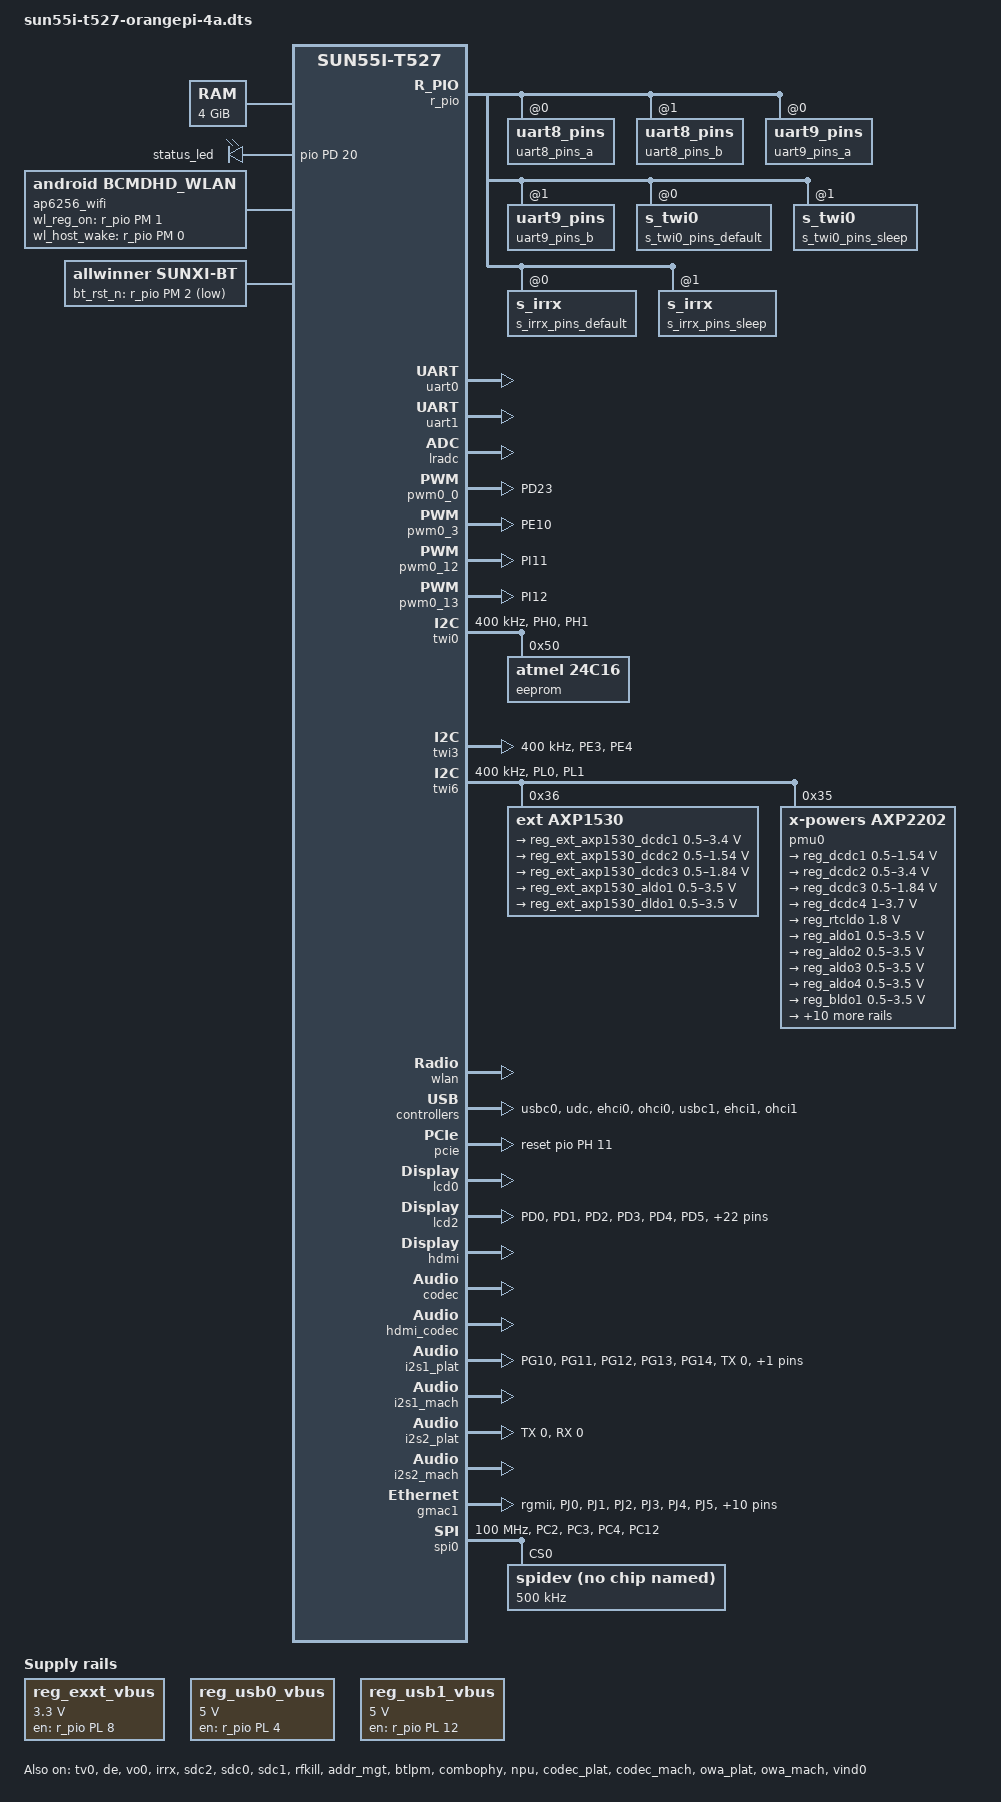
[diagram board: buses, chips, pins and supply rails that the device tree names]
/*
 * Allwinner Technology CO., Ltd.
 */

/dts-v1/;

#include "sun55iw3p1.dtsi"

/{
	board = "A527", "A527-PRO2-AXP717C";
	compatible = "allwinner,a523", "arm,sun55iw3p1";

	chosen {
		stdout-path = "serial0:115200n8";
	};

	memory {
		reg = <0x00 0x40000000 0x01 0x00>;
		device_type = "memory";
	};

	aliases {
		pmu0 = &pmu0;
		axp1530 = &axp1530;
		serial0 = &uart0;
		lcd0 = &lcd0;
		hdmi = &hdmi;
		//reg-tcs0 = &reg_tcs0;
		//reg-sy0 = &reg_sy0;
		reg-axp1530 = &reg_ext_axp1530_dcdc1;
		//tcs0 = &tcs0;
		//sy0 = &sy0;
		cpu-ext = &cpu4;
		standby-param = &standby_param;
		arisc-config = &arisc_config;
	};

        leds: gpio-leds {
		compatible = "gpio-leds";
		pinctrl-names = "default";
		status = "okay";

		status_led@0 {
			gpios = <&pio PD 20 GPIO_ACTIVE_HIGH>;
			label = "status_led";
			linux,default-trigger = "heartbeat";
			linux,default-trigger-delay-ms = <0>;
		};
	};

	ap6256_wifi: ap6256_wifi {
		compatible = "android,bcmdhd_wlan";
		gpio_wl_reg_on = <&r_pio PM 1 GPIO_ACTIVE_HIGH>;
		gpio_wl_host_wake = <&r_pio PM 0 GPIO_ACTIVE_HIGH>;
	};

        //unisoc_uwe_bsp: uwe-bsp {
        //        compatible = "unisoc,uwe_bsp";
        //        wl-reg-on = <&r_pio PM 1 GPIO_ACTIVE_HIGH>;
        //        bt-reg-on = <&r_pio PM 2 GPIO_ACTIVE_LOW>;
        //        wl-wake-host-gpio = <&r_pio PM 0 GPIO_ACTIVE_HIGH>;
        //        bt-wake-host-gpio = <&r_pio PM 5 GPIO_ACTIVE_HIGH>;
        //        //sdio-ext-int-gpio = <&gpio2 RK_PC1 GPIO_ACTIVE_HIGH>;
        //        unisoc,btwf-file-name = "/vendor/etc/firmware/wcnmodem.bin";
        //        //adma-tx;
        //        //adma-rx;
        //        data-irq;
        //        blksz-512;
        //        keep-power-on;
        //        status = "okay";
        //};

        //sprd-mtty {
        //        compatible = "sprd,mtty";
        //        sprd,name = "ttyBT";
        //        status = "okay";
        //};

	reg_exxt_vbus: exxt-vbus {
		compatible = "regulator-fixed";
		regulator-name = "exxxxt-vbus";
		regulator-min-microvolt = <3300000>;
		regulator-max-microvolt = <3300000>;
		regulator-enable-ramp-delay = <1000>;
		gpio = <&r_pio PL 8 GPIO_ACTIVE_HIGH>;
		regulator-always-on;
		regulator-boot-on;
		enable-active-high;
	};

	reg_usb0_vbus: usb0-vbus {
		compatible = "regulator-fixed";
		regulator-name = "usb0-vbus";
		regulator-min-microvolt = <5000000>;
		regulator-max-microvolt = <5000000>;
		regulator-enable-ramp-delay = <1000>;
		gpio = <&r_pio PL 4 GPIO_ACTIVE_HIGH>;
		regulator-always-on;
		regulator-boot-on;
		enable-active-high;
	};

	reg_usb1_vbus: usb1-vbus {
		compatible = "regulator-fixed";
		regulator-name = "usb1-vbus";
		regulator-min-microvolt = <5000000>;
		regulator-max-microvolt = <5000000>;
		regulator-enable-ramp-delay = <1000>;
		gpio = <&r_pio PL 12 GPIO_ACTIVE_HIGH>;
		enable-active-high;
	};

	standby_param: standby_param {
		vdd-cpu = <0x00000001>;
		vdd-cpub = <0x00000001>;
		vdd-ndr = <0x00000004>;
		vdd-sys = <0x00000002>;
		vcc-pll = <0x00000080>;
		vcc-io  = <0x00004000>;

		osc24m-on = <0x0>;
	};

	arisc_config: arisc_config {
		s_uart_config{
			pins = "PL2", "PL3";
			function = <2>, <2>;
			status = "disabled";
		};
	};

	edp_panel: edp_panel {
		compatible = "edp-general-panel";
		status = "disabled";
		power0-supply = <&reg_dcdc4>;
		enable0-gpios = <&pio PD 21 GPIO_ACTIVE_HIGH>;

		backlight = <&edp_panel_backlight>;

		panel-timing {
			clock-frequency = <125000000>; /* pixel clock */
			hactive = <1920>;
			hback-porch = <180>;
			hfront-porch = <120>;
			hsync-len = <32>;
			vactive = <1080>;
			vback-porch = <10>;
			vfront-porch = <10>;
			vsync-len = <20>;
			/* hor_sync_polarity */
			hsync-active = <0>;
			/* ver_sync_polarity */
			vsync-active = <0>;

			// unused now
			/*
			de-active = <1>;
			pixelclk-active = <1>;
			syncclk-active = <0>;
			interlaced;
			doublescan;
			doubleclk;
			*/
		};
		ports {
			#address-cells = <1>;
			#size-cells = <0>;
			panel_edp_in: port@0 {
				#address-cells = <1>;
				#size-cells = <0>;
				reg = <0>;
				edp_panel_in: endpoint@0 {
					reg = <0>;
					remote-endpoint = <&edp_panel_out>;
				};
			};
		};
	};

	edp_panel_backlight: edp-panel-backlight {
		compatible = "pwm-backlight";
		status = "disabled";
		brightness-levels = <
			  0   1   2   3   4   5   6   7
			  8   9  10  11  12  13  14  15
			 16  17  18  19  20  21  22  23
			 24  25  26  27  28  29  30  31
			 32  33  34  35  36  37  38  39
			 40  41  42  43  44  45  46  47
			 48  49  50  51  52  53  54  55
			 56  57  58  59  60  61  62  63
			 64  65  66  67  68  69  70  71
			 72  73  74  75  76  77  78  79
			 80  81  82  83  84  85  86  87
			 88  89  90  91  92  93  94  95
			 96  97  98  99 100 101 102 103
			104 105 106 107 108 109 110 111
			112 113 114 115 116 117 118 119
			120 121 122 123 124 125 126 127
			128 129 130 131 132 133 134 135
			136 137 138 139 140 141 142 143
			144 145 146 147 148 149 150 151
			152 153 154 155 156 157 158 159
			160 161 162 163 164 165 166 167
			168 169 170 171 172 173 174 175
			176 177 178 179 180 181 182 183
			184 185 186 187 188 189 190 191
			192 193 194 195 196 197 198 199
			200 201 202 203 204 205 206 207
			208 209 210 211 212 213 214 215
			216 217 218 219 220 221 222 223
			224 225 226 227 228 229 230 231
			232 233 234 235 236 237 238 239
			240 241 242 243 244 245 246 247
			248 249 250 251 252 253 254 255>;
		default-brightness-level = <200>;
		pwms = <&pwm0 0 50000 0>;
	};

	backlight0: backlight0 {
		compatible = "pwm-backlight";
		status = "disabled";
		brightness-levels = <
			  0   1   2   3   4   5   6   7
			  8   9  10  11  12  13  14  15
			 16  17  18  19  20  21  22  23
			 24  25  26  27  28  29  30  31
			 32  33  34  35  36  37  38  39
			 40  41  42  43  44  45  46  47
			 48  49  50  51  52  53  54  55
			 56  57  58  59  60  61  62  63
			 64  65  66  67  68  69  70  71
			 72  73  74  75  76  77  78  79
			 80  81  82  83  84  85  86  87
			 88  89  90  91  92  93  94  95
			 96  97  98  99 100 101 102 103
			104 105 106 107 108 109 110 111
			112 113 114 115 116 117 118 119
			120 121 122 123 124 125 126 127
			128 129 130 131 132 133 134 135
			136 137 138 139 140 141 142 143
			144 145 146 147 148 149 150 151
			152 153 154 155 156 157 158 159
			160 161 162 163 164 165 166 167
			168 169 170 171 172 173 174 175
			176 177 178 179 180 181 182 183
			184 185 186 187 188 189 190 191
			192 193 194 195 196 197 198 199
			200 201 202 203 204 205 206 207
			208 209 210 211 212 213 214 215
			216 217 218 219 220 221 222 223
			224 225 226 227 228 229 230 231
			232 233 234 235 236 237 238 239
			240 241 242 243 244 245 246 247
			248 249 250 251 252 253 254 255>;
		default-brightness-level = <200>;
		pwms = <&pwm0 3 50000 0>;
	};

	panel_0: panel_0@0 {
		compatible = "allwinner,panel-dsi";
		status = "disabled";
		reg = <0>;
		power0-supply = <&reg_cldo4>;
		power1-supply = <&reg_cldo1>;

		enable0-gpios = <&pio PE 13 GPIO_ACTIVE_HIGH>;
		reset-gpios = <&pio PE 14 GPIO_ACTIVE_HIGH>;
		reset-num = <1>;
		backlight = <&backlight0>;
		dsi,flags = <MIPI_DSI_MODE_VIDEO>;
		dsi,lanes = <4>;
		dsi,format = <0>;
		enable-delay-ms = <500>;
		reset-delay-ms = <500>;
		panel-init-sequence = [
				39 10 04 FF 98 81 03

				39 10 02 01 00
				39 10 02 02 00
				39 10 02 03 53
				39 10 02 04 D3
				39 10 02 05 00
				39 10 02 06 0D
				39 10 02 07 08
				39 10 02 08 00
				39 10 02 09 00
				39 10 02 0a 00
				39 10 02 0b 00
				39 10 02 0c 00
				39 10 02 0d 00
				39 10 02 0e 00
				39 10 02 0f 28
				39 10 02 10 28
				39 10 02 11 00
				39 10 02 12 00
				39 10 02 13 00
				39 10 02 14 00
				39 10 02 15 00
				39 10 02 16 00
				39 10 02 17 00
				39 10 02 18 00
				39 10 02 19 00
				39 10 02 1a 00
				39 10 02 1b 00
				39 10 02 1c 00
				39 10 02 1d 00
				39 10 02 1e 40
				39 10 02 1f 80
				39 10 02 20 06
				39 10 02 21 01
				39 10 02 22 00
				39 10 02 23 00
				39 10 02 24 00
				39 10 02 25 00
				39 10 02 26 00
				39 10 02 27 00
				39 10 02 28 33
				39 10 02 29 33
				39 10 02 2a 00
				39 10 02 2b 00
				39 10 02 2c 00
				39 10 02 2d 00
				39 10 02 2e 00
				39 10 02 2f 00
				39 10 02 30 00
				39 10 02 31 00
				39 10 02 32 00
				39 10 02 33 00
				39 10 02 34 03
				39 10 02 35 00
				39 10 02 36 00
				39 10 02 37 00
				39 10 02 38 96
				39 10 02 39 00
				39 10 02 3a 00 
				39 10 02 3b 00
				39 10 02 3c 00
				39 10 02 3d 00
				39 10 02 3e 00
				39 10 02 3f 00
				39 10 02 40 00
				39 10 02 41 00
				39 10 02 42 00
				39 10 02 43 00  
				39 10 02 44 00

				39 10 02 50 00
				39 10 02 51 23
				39 10 02 52 45
				39 10 02 53 67
				39 10 02 54 89
				39 10 02 55 AB
				39 10 02 56 01
				39 10 02 57 23
				39 10 02 58 45
				39 10 02 59 67
				39 10 02 5a 89
				39 10 02 5b AB
				39 10 02 5c CD
				39 10 02 5d EF

				39 10 02 5e 00
				39 10 02 5f 08
				39 10 02 60 08
				39 10 02 61 06
				39 10 02 62 06
				39 10 02 63 01
				39 10 02 64 01
				39 10 02 65 00
				39 10 02 66 00
				39 10 02 67 02
				39 10 02 68 15
				39 10 02 69 15
				39 10 02 6a 14
				39 10 02 6b 14
				39 10 02 6c 0D
				39 10 02 6d 0D
				39 10 02 6e 0C
				39 10 02 6f 0C
				39 10 02 70 0F
				39 10 02 71 0F
				39 10 02 72 0E
				39 10 02 73 0E
				39 10 02 74 02

				39 10 02 75 08
				39 10 02 76 08
				39 10 02 77 06
				39 10 02 78 06
				39 10 02 79 01
				39 10 02 7a 01
				39 10 02 7b 00
				39 10 02 7c 00
				39 10 02 7d 02
				39 10 02 7e 15
				39 10 02 7f 15
				39 10 02 80 14
				39 10 02 81 14
				39 10 02 82 0D
				39 10 02 83 0D
				39 10 02 84 0C
				39 10 02 85 0C
				39 10 02 86 0F
				39 10 02 87 0F
				39 10 02 88 0E
				39 10 02 89 0E
				39 10 02 8A 02

				39 10 04 FF 98 81 04

				39 10 02 6E 2B
				39 10 02 6F 37
				39 10 02 3A A4
				39 10 02 8D 1A
				39 10 02 87 BA
				39 10 02 B2 D1
				39 10 02 88 0B
				39 10 02 38 01
				39 10 02 39 00
				39 10 02 B5 07
				39 10 02 31 75
				39 10 02 3B 98

				39 10 04 FF 98 81 01
				39 10 02 43 33
				39 10 02 22 0A
				39 10 02 31 00
				39 10 02 53 48
				39 10 02 55 48
				39 10 02 50 99
				39 10 02 51 94
				39 10 02 60 10
				39 10 02 62 20

				39 10 02 A0 00
				39 10 02 A1 00
				39 10 02 A2 15
				39 10 02 A3 14
				39 10 02 A4 1B
				39 10 02 A5 2F
				39 10 02 A6 25
				39 10 02 A7 24
				39 10 02 A8 80
				39 10 02 A9 1F
				39 10 02 AA 2C
				39 10 02 AB 6C
				39 10 02 AC 16
				39 10 02 AD 14
				39 10 02 AE 4D
				39 10 02 AF 20
				39 10 02 B0 29
				39 10 02 B1 4F
				39 10 02 B2 5F
				39 10 02 B3 23

				39 10 02 C0 00
				39 10 02 C1 2E
				39 10 02 C2 3B
				39 10 02 C3 15
				39 10 02 C4 16
				39 10 02 C5 28
				39 10 02 C6 1A
				39 10 02 C7 1C
				39 10 02 C8 A7
				39 10 02 C9 1B
				39 10 02 CA 28
				39 10 02 CB 92
				39 10 02 CC 1F
				39 10 02 CD 1C
				39 10 02 CE 4B
				39 10 02 CF 1F
				39 10 02 D0 28
				39 10 02 D1 4E
				39 10 02 D2 5C
				39 10 02 D3 23

				39 10 04 FF 98 81 00
				39 10 02 11 00
				39 78 02 29 00
				39 10 02 35 00
		];

		panel-exit-sequence = [
			05 14 01 28
			05 50 01 10
		];

		display-timings {
			native-mode = <&dsi1_timing0>;

			dsi1_timing0: timing0 {
				clock-frequency = <68215200>;
				hback-porch = <20>;
				hactive = <800>;
				hfront-porch = <20>;
				hsync-len = <20>;
				vback-porch = <8>;
				vactive = <1280>;
				vfront-porch = <30>;
				vsync-len = <4>;
			};
		};
		port {
			panel0_in: endpoint@0 {
				reg = <0>;
				remote-endpoint = <&panel_output_0>;
			};
		};
	};
};

/* HDMI DRM */
&tv0 {
        status = "okay";
};

&tv1 {
        status = "disabled";
};

&de {
	chn_cfg_mode = <3>;
	status = "okay";
};

&vo0 {
	status = "okay";
};

//&vo1 {
//	status = "disabled";
//};

&dlcd1 {
	status = "disabled";
};

&dsi1combophy {
	status = "disabled";
};

&dsi1 {
	status = "disabled";
	pinctrl-0 = <&dsi1_4lane_pins_a>;
	pinctrl-1 = <&dsi1_4lane_pins_b>;
	pinctrl-names = "active","sleep";

	ports {
		dsi1_out: port@1{
			dsi1_out_panel: endpoint {
				remote-endpoint = <&panel_input>;
			};
		};
	};
	panel: panel@0 {
		compatible = "allwinner,virtual-panel";
		status = "disabled";
		reg = <0>;
		ports {
			panel_in: port@0 {
				reg = <0>;
				panel_input: endpoint@0 {
					reg = <0>;
					remote-endpoint = <&dsi1_out_panel>;
				};
			};
			panel_out: port@1 {
				reg = <1>;
				panel_output_0: endpoint@0 {
					reg = <0>;
					remote-endpoint = <&panel0_in>;
				};
			};
		};
	};
};

&drm_edp {
	status = "disabled";

	//edp_ssc_en = <0>;
	//edp_ssc_mode = <0>;
	//edp_psr_support = <0>;
	edp_colordepth = <8>; /* 6/8/10/12/16 */
	edp_color_fmt = <0>; /* 0:RGB  1: YUV444  2: YUV422 */

	//lane1_sw = <0>;
	//lane1_pre = <0>;
	//lane2_sw = <0>;
	//lane2_pre = <0>;
	//lane3_sw = <0>;
	//lane3_pre = <0>;
	//efficient_training = <0>;

	//sink_capacity_prefer = <1>;
	//edid_timings_prefer = <1>;
	//timings_fixed = <1>;

	vcc-edp-supply = <&reg_bldo3>;
	vdd-edp-supply = <&reg_dcdc2>;
	panel = <&edp_panel>;

	ports {
		edp_out: port@1 {
			edp_panel_out: endpoint@0 {
				reg = <0>;
				remote-endpoint = <&edp_panel_in>;
			};
		};
	};
};

&r_pio {
	uart8_pins_a: uart8_pins@0 {
		pins = "PL2", "PL3";
		function = "s_uart0";
	};

	uart8_pins_b: uart8_pins@1 {
		pins = "PL2", "PL3";
		function = "gpio_in";
	};

	uart9_pins_a: uart9_pins@0 {
		pins = "PM0", "PM1";
		function = "s_uart1";
	};

	uart9_pins_b: uart9_pins@1 {
		pins = "PM0", "PM1";
		function = "gpio_in";
	};

	s_twi0_pins_default: s_twi0@0 {
		pins = "PL0", "PL1";
		function = "s_twi0";
		drive-strength = <10>;
		bias-pull-up;
	};

	s_twi0_pins_sleep: s_twi0@1 {
		pins = "PL0", "PL1";
		function = "gpio_in";
	};

	s_irrx_pins_default: s_irrx@0 {
		pins = "PL11";
		function = "s_cir";
	};

	s_irrx_pins_sleep: s_irrx@1 {
	        pins = "PL11";
		function = "gpio_in";
	};
};

&pio {
	vcc-pg-supply = <&reg_pio1_8>;
	vcc-pc-supply = <&reg_pio1_8>;
	vcc-pf-supply = <&reg_pio1_8>;
	vcc-pfo-supply = <&reg_pio3_3>;

	uart0_pins_a: uart0_pins@0 {
		pins = "", "";
		function = "uart0";
	};

	uart0_pins_b: uart0_pins@1 {
		pins = "", "";
		function = "gpio_in";
	};

	uart2_pins_a: uart2_pins@0 {
		pins = "PB0", "PB1";
		function = "uart2";
	};

	uart2_pins_b: uart2_pins@1 {
		pins = "PB0", "PB1";
		function = "gpio_in";
	};

	uart3_pins_a: uart3_pins@0 {
		pins = "PI11", "PI12";
		function = "uart3";
	};

	uart3_pins_b: uart3_pins@1 {
		pins = "PI11", "PI12";
		function = "gpio_in";
	};

	uart4_pins_a: uart4_pins@0 {
		pins = "PI0", "PI1";
		function = "uart4";
	};

	uart4_pins_b: uart4_pins@1 {
		pins = "PI0", "PI1";
		function = "gpio_in";
	};

	uart5_pins_a: uart5_pins@0 {
		pins = "PI2", "PI3";
		function = "uart5";
	};

	uart5_pins_b: uart5_pins@1 {
		pins = "PI2", "PI3";
		function = "gpio_in";
	};

	uart6_pins_a: uart6_pins@0 {
		pins = "PI6", "PI7";
		function = "uart6";
	};

	uart6_pins_b: uart6_pins@1 {
		pins = "PI6", "PI7";
		function = "gpio_in";
	};

	uart7_pins_a: uart7_pins@0 {
		pins = "PB13", "PB14";
		function = "uart7";
	};

	uart7_pins_b: uart7_pins@1 {
		pins = "PB13", "PB14";
		function = "gpio_in";
	};

	pwm0_0_pin_active: pwm0_0@0 {
		pins = "PD23";
		function = "pwm0_0";
		drive-strength = <10>;
	};
	
	pwm0_0_pin_sleep: pwm0_0@1 {
		pins = "PD23";
		function = "gpio_in";
	};
	
	pwm0_1_pin_active: pwm0_1@0 {
		pins = "PI0";
		function = "pwm0_1";
		drive-strength = <10>;
	};
	
	pwm0_1_pin_sleep: pwm0_1@1 {
		pins = "PI0";
		function = "gpio_in";
	};
	
	pwm0_2_pin_active: pwm0_2@0 {
		pins = "PB11";
		function = "pwm0_2";
		drive-strength = <10>;
	};
	
	pwm0_2_pin_sleep: pwm0_2@1 {
		pins = "PB11";
		function = "gpio_in";
	};
	
	pwm0_3_pin_active: pwm0_3@0 {
		pins = "PE10";
		function = "pwm0_3";
		drive-strength = <10>;
	};
	
	pwm0_3_pin_sleep: pwm0_3@1 {
		pins = "PE10";
		function = "gpio_in";
	};
	
	pwm0_4_pin_active: pwm0_4@0 {
		pins = "PB13";
		function = "pwm0_4";
		drive-strength = <10>;
	};
	
	pwm0_4_pin_sleep: pwm0_4@1 {
		pins = "PB13";
		function = "gpio_in";
	};
	
	pwm0_5_pin_active: pwm0_5@0 {
		pins = "PB14";
		function = "pwm0_5";
		drive-strength = <10>;
	};
	
	pwm0_5_pin_sleep: pwm0_5@1 {
		pins = "PB14";
		function = "gpio_in";
	};
	
	pwm0_6_pin_active: pwm0_6@0 {
		pins = "PB0";
		function = "pwm0_6";
		drive-strength = <10>;
	};
	
	pwm0_6_pin_sleep: pwm0_6@1 {
		pins = "PB0";
		function = "gpio_in";
	};
	
	pwm0_7_pin_active: pwm0_7@0 {
		pins = "PB1";
		function = "pwm0_7";
		drive-strength = <10>;
	};
	
	pwm0_7_pin_sleep: pwm0_7@1 {
		pins = "PB1";
		function = "gpio_in";
	};

	pwm0_8_pin_active: pwm0_8@0 {
		pins = "PB4";
		function = "pwm0_8";
		drive-strength = <10>;
	};

	pwm0_8_pin_sleep: pwm0_8@1 {
		pins = "PB4";
		function = "gpio_in";
	};

	pwm0_9_pin_active: pwm0_9@0 {
		pins = "PB5";
		function = "pwm0_9";
		drive-strength = <10>;
	};
	
	pwm0_9_pin_sleep: pwm0_9@1 {
		pins = "PB5";
		function = "gpio_in";
	};
	
	pwm0_10_pin_active: pwm0_10@0 {
		pins = "PB6";
		function = "pwm0_10";
		drive-strength = <10>;
	};
	
	pwm0_10_pin_sleep: pwm0_10@1 {
		pins = "PB6";
		function = "gpio_in";
	};
	
	pwm0_11_pin_active: pwm0_11@0 {
		pins = "PB7";
		function = "pwm0_11";
		drive-strength = <10>;
	};
	
	pwm0_11_pin_sleep: pwm0_11@1 {
		pins = "PB7";
		function = "gpio_in";
	};

	pwm0_12_pin_active: pwm0_12@0 {
		pins = "PI11";
		function = "pwm0_12";
		drive-strength = <10>;
	};

	pwm0_12_pin_sleep: pwm0_12@1 {
		pins = "PI11";
		function = "gpio_in";
	};

	pwm0_13_pin_active: pwm0_13@0 {
		pins = "PI12";
		function = "pwm0_13";
		drive-strength = <10>;
	};

	pwm0_13_pin_sleep: pwm0_13@1 {
		pins = "PI12";
		function = "gpio_in";
	};

	pwm0_14_pin_active: pwm0_14@0 {
		pins = "PI13";
		function = "pwm0_14";
		drive-strength = <10>;
	};
	
	pwm0_14_pin_sleep: pwm0_14@1 {
		pins = "PI13";
		function = "gpio_in";
	};
	
	pwm0_15_pin_active: pwm0_15@0 {
		pins = "PI14";
		function = "pwm0_15";
		drive-strength = <10>;
	};
	
	pwm0_15_pin_sleep: pwm0_15@1 {
		pins = "PI14";
		function = "gpio_in";
	};

	ledc_pins_a: ledc@0 {
		pins = "PE5";
		function = "ledc";
		drive-strength = <10>;
	};

	ledc_pins_b: ledc@1 {
		pins = "PE5";
		function = "gpio_in";
	};

	irrx_pins_default: irrx@0 {
		pins = "PH19";
		function = "cir";
	};

	irrx_pins_sleep: irrx@1 {
	        pins = "PH19";
	        function = "gpio_in";
	};

	irtx_pins_default: irtx@0 {
		pins = "PH18";
		function = "cir";
	};

	irtx_pins_sleep: irtx@1 {
		pins = "PH18";
		function = "gpio_in";
	};

	twi0_pins_default: twi0@0 {
		pins = "PH0", "PH1";
		function = "twi0";
		drive-strength = <40>;
		bias-pull-up;
	};

	twi0_pins_sleep: twi0@1 {
		pins = "PH0", "PH1";
		function = "gpio_in";
	};

	twi1_pins_default: twi1@0 {
		pins = "PB4", "PB5";
		function = "twi1";
		drive-strength = <10>;
		bias-pull-up;
	};

	twi1_pins_sleep: twi1@1 {
		pins = "PB4", "PB5";
		function = "gpio_in";
	};

	twi3_pins_default: twi3@0 {
		pins = "PE3", "PE4";
		function = "twi3";
		drive-strength = <40>;
		bias-pull-up;
	};

	twi3_pins_sleep: twi3@1 {
		pins = "PE3", "PE4";
		function = "twi3";
		drive-strength = <40>;
		bias-pull-up;
	};

	twi4_pins_default: twi4@0 {
		pins = "PI0", "PI1";
		function = "twi4";
		drive-strength = <20>;
		bias-pull-up;
	};

	twi4_pins_sleep: twi4@1 {
		pins = "PI0", "PI1";
		function = "gpio_in";
	};

	twi5_pins_default: twi5@0 {
		pins = "PI8", "PI9";
		function = "twi5";
		drive-strength = <10>;
		bias-pull-up;
	};

	twi5_pins_sleep: twi5@1 {
		pins = "PI8", "PI9";
		function = "gpio_in";
	};

	rgb24_pins_a: rgb24@0 {
		pins = "PD0", "PD1", "PD2", "PD3", "PD4", "PD5", "PD6", "PD7", "PD8", "PD9", \
			"PD10", "PD11", "PD12", "PD13", "PD14", "PD15", "PD16", "PD17", "PD18", "PD19", \
			"PD20", "PD21", "PD22","PD23","PD24","PD25","PD26","PD27";
		      function = "dpss";
		      drive-strength = <30>;
	      };
	rgb24_pins_b: rgb24@1 {
		pins = "PD0", "PD1", "PD2", "PD3", "PD4", "PD5", "PD6", "PD7", "PD8", "PD9", \
			"PD10", "PD11", "PD12", "PD13", "PD14", "PD15", "PD16", "PD17", "PD18", "PD19", \
			"PD20", "PD21", "PD22", "PD23","PD24","PD25","PD26","PD27";
		      function = "gpio_in";
	      };
	lvds0_pins_a: lvds0@0 {
		pins = "PD0", "PD1", "PD2", "PD3", "PD4", "PD5", "PD6", "PD7", "PD8", "PD9";
		      function = "lvds";
		      drive-strength = <30>;
	      };
	lvds0_pins_b: lvds0@1 {
		      pins = "PD0", "PD1", "PD2", "PD3", "PD4", "PD5", "PD6", "PD7", "PD8", "PD9";
		      function = "gpio_in";
	      };

	csi_mclk3_pins_a: csi_mclk3@0 {
		pins = "PE10";
		function = "mipi3";
		drive-strength = <20>;
	};

	csi_mclk3_pins_b: csi_mclk3@1 {
		pins = "PE10";
		function = "gpio_in";
	};

	ncsi_pins_a: ncsi@0 {
		pins = "PK12", "PK14", "PK15",
		"PK16", "PK17", "PK18", "PK19",
		"PK20", "PK21", "PK22", "PK23",
		"PE6", "PE7", "PE8", "PE9",
		"PE10", "PE11", "PE12", "PE15";
		function = "ncsi";
		drive-strength = <20>;
	};

	ncsi_pins_b: ncsi@1 {
		pins = "PK12", "PK14", "PK15",
		"PK16", "PK17", "PK18", "PK19",
		"PK20", "PK21", "PK22", "PK23",
		"PE6", "PE7", "PE8", "PE9",
		"PE10", "PE11", "PE12", "PE15";
		function = "gpio_in";
	};

	i2s1_pins_a: i2s1@0 {
		pins = "PG10", "PG11", "PG12";
		function = "i2s1";
		drive-strength = <20>;
		bias-disable;
	};

	i2s1_pins_b: i2s1@1 {
		pins = "PG10", "PG11", "PG12", "PG13", "PG14";
		function = "io_disabled";
		drive-strength = <20>;
		bias-disable;
	};

	i2s1_pins_c: i2s1@2 {
		pins = "PG13";
		function = "i2s1_dout";
		drive-strength = <20>;
		bias-disable;
	};

	i2s1_pins_d: i2s1@3 {
		pins = "PG14";
		function = "i2s1_din";
		drive-strength = <20>;
		bias-disable;
	};

	owa_pins_a: owa@0 {
		pins = "PH7";
		function = "owa";
		drive-strength = <20>;
		bias-disable;
	};

	owa_pins_b: owa@1 {
		pins = "PH7";
		function = "io_disabled";
		drive-strength = <20>;
		bias-disable;
	};

	nand0_pins_default: nand0@0 {
		pins = "PC0", "PC1", "PC2", "PC5",
			 "PC8", "PC9", "PC10", "PC11",
			 "PC12", "PC13", "PC14", "PC15",
			 "PC16";
		function = "nand0";
		drive-strength = <30>;
	};

	nand0_pins_rb: nand0@1 {
		pins = "PC4", "PC6", "PC3", "PC7";
		function = "nand0";
		drive-strength = <30>;
		bias-pull-up;   /* only RB&CE should be pulled up */
	};

	nand0_pins_sleep: nand0@2 {
		pins = "PC0", "PC1", "PC2", "PC3",
			 "PC4", "PC5", "PC6", "PC7",
			 "PC8", "PC9", "PC10", "PC11",
			 "PC12", "PC13", "PC14", "PC15",
			 "PC16";
		function = "io_disabled";
		drive-strength = <10>;
	};

	i2s0_pins_a: i2s0@0 {
		pins = "PB4", "PB5", "PB6";
		function = "i2s0";
		drive-strength = <20>;
		bias-disable;
	};

	i2s0_pins_b: i2s0@1 {
		pins = "PB4", "PB5", "PB6", "PB7", "PB8";
		function = "io_disabled";
		drive-strength = <20>;
		bias-disable;
	};

	i2s0_pins_c: i2s0@2 {
		pins = "PB7";
		function = "i2s0_dout";
		drive-strength = <20>;
		bias-disable;
	};

	i2s0_pins_d: i2s0@3 {
		pins = "PB8";
		function = "i2s0_din";
		drive-strength = <20>;
		bias-disable;
	};

	gmac1_pins_default: gmac1@0 {
		pins = "PJ0", "PJ1", "PJ2", "PJ3",
			"PJ4", "PJ5", "PJ6", "PJ7",
			"PJ8", "PJ9", "PJ10", "PJ11",
			"PJ12","PJ13", "PJ14", "PJ15";
		drive-strength = <40>;
		function = "gmac1";
		bias-pull-up;
	};

	gmac1_pins_sleep: gmac1@1 {
		pins = "PJ0", "PJ1", "PJ2", "PJ3",
			"PJ4", "PJ5", "PJ6", "PJ7",
			"PJ8", "PJ9", "PJ10", "PJ11",
			"PJ12","PJ13", "PJ14", "PJ15";
		function = "gpio_in";
	};

	spi0_pin_default: spi0_pin_default{
		pins = "PC2","PC3","PC4","PC12";
		function = "spi0";
	};

	spi0_pin_sleep: spi0_pin_sleep{
		pins = "PC2","PC3","PC4","PC12";
		function = "gpio_in";
	};

	spi1_pin_default: spi1_pin_default{
		pins = "PI2","PI3","PI4","PI5";
		function = "spi1";
	};

	spi1_pin_sleep: spi1_pin_sleep{
		pins = "PI2","PI3","PI4","PI5";
		function = "gpio_in";
	};

	spi2_pin_default: spi2_pin_default{
		pins = "PB0","PB1","PB2","PB3";
		function = "spi2";
	};

	spi2_pin_sleep: spi2_pin_sleep{
		pins = "PB0","PB1","PB2","PB3";
		function = "gpio_in";
	};
};

&soc {
	auto_print@54321 {
		reg = <0x0 0x54321 0x0 0x0>;
		device_type = "auto_print";
		status = "okay";
	};

	hall_para {
		hall_name = "MH248";
		status = "okay";
		hall_int_port = <&r_pio PL 9 GPIO_ACTIVE_LOW>;
	};

};

&uart0 {
	pinctrl-names = "default", "sleep";
	pinctrl-0 = <&uart0_pins_a>;
	pinctrl-1 = <&uart0_pins_b>;
	uart-supply = <&reg_cldo3>;
	status = "okay";
};

&uart1 {
	status = "okay";
};

&uart2 {
	pinctrl-names = "default", "sleep";
	pinctrl-0 = <&uart2_pins_a>;
	pinctrl-1 = <&uart2_pins_b>;
	status = "disabled";
};

&uart3 {
	pinctrl-names = "default", "sleep";
	pinctrl-0 = <&uart3_pins_a>;
	pinctrl-1 = <&uart3_pins_b>;
	status = "disabled";
};

&uart4 {
	pinctrl-names = "default", "sleep";
	pinctrl-0 = <&uart4_pins_a>;
	pinctrl-1 = <&uart4_pins_b>;
	status = "disabled";
};

&uart5 {
	pinctrl-names = "default", "sleep";
	pinctrl-0 = <&uart5_pins_a>;
	pinctrl-1 = <&uart5_pins_b>;
	status = "disabled";
};

&uart6 {
	pinctrl-names = "default", "sleep";
	pinctrl-0 = <&uart6_pins_a>;
	pinctrl-1 = <&uart6_pins_b>;
	status = "disabled";
};

&uart7 {
	pinctrl-names = "default", "sleep";
	pinctrl-0 = <&uart7_pins_a>;
	pinctrl-1 = <&uart7_pins_b>;
	status = "disabled";
};

&uart8 {
	pinctrl-names = "default", "sleep";
	pinctrl-0 = <&uart8_pins_a>;
	pinctrl-1 = <&uart8_pins_b>;
	status = "disabled";
};

&uart9 {
	pinctrl-names = "default", "sleep";
	pinctrl-0 = <&uart9_pins_a>;
	pinctrl-1 = <&uart9_pins_b>;
	status = "disabled";
};

&lradc {
	key_cnt = <2>;
	key0 = <646 115>;
	key1 = <900 114>;
	key_debounce;
	debounce_value = <150>;
	status = "okay";
};

&gpadc0 {
	channel_num = <2>;
	channel_select = <3>;
	channel_data_select = <3>;
	channel_compare_select = <3>;
	channel_cld_select = <3>;
	channel_chd_select = <3>;
	channel0_compare_lowdata = <1700000>;
	channel0_compare_higdata = <1200000>;
	channel1_compare_lowdata = <460000>;
	channel1_compare_higdata = <1200000>;
	status = "disabled";
};

&gpadc1 {
	channel_num = <2>;
	channel_select = <3>;
	channel_data_select = <3>;
	channel_compare_select = <3>;
	channel_cld_select = <3>;
	channel_chd_select = <3>;
	channel0_compare_lowdata = <1700000>;
	channel0_compare_higdata = <1200000>;
	channel1_compare_lowdata = <460000>;
	channel1_compare_higdata = <1200000>;
	status = "disabled";
};

&pwm0_0 {
	pinctrl-names = "active", "sleep";
	pinctrl-0 = <&pwm0_0_pin_active>;
	pinctrl-1 = <&pwm0_0_pin_sleep>;
	status = "okay";
};

&pwm0_1 {
	pinctrl-names = "active", "sleep";
	pinctrl-0 = <&pwm0_1_pin_active>;
	pinctrl-1 = <&pwm0_1_pin_sleep>;
	status = "disabled";
};

&pwm0_2 {
	pinctrl-names = "active", "sleep";
	pinctrl-0 = <&pwm0_2_pin_active>;
	pinctrl-1 = <&pwm0_2_pin_sleep>;
	status = "disabled";
};

&pwm0_3 {
	pinctrl-names = "active", "sleep";
	pinctrl-0 = <&pwm0_3_pin_active>;
	pinctrl-1 = <&pwm0_3_pin_sleep>;
	status = "okay";
};

&pwm0_4 {
	pinctrl-names = "active", "sleep";
	pinctrl-0 = <&pwm0_4_pin_active>;
	pinctrl-1 = <&pwm0_4_pin_sleep>;
	status = "disabled";
};

&pwm0_5 {
	pinctrl-names = "active", "sleep";
	pinctrl-0 = <&pwm0_5_pin_active>;
	pinctrl-1 = <&pwm0_5_pin_sleep>;
	status = "disabled";
};

&pwm0_6 {
	pinctrl-names = "active", "sleep";
	pinctrl-0 = <&pwm0_6_pin_active>;
	pinctrl-1 = <&pwm0_6_pin_sleep>;
	status = "disabled";
};

&pwm0_7 {
	pinctrl-names = "active", "sleep";
	pinctrl-0 = <&pwm0_7_pin_active>;
	pinctrl-1 = <&pwm0_7_pin_sleep>;
	status = "disabled";
};

&pwm0_8 {
	pinctrl-names = "active", "sleep";
	pinctrl-0 = <&pwm0_8_pin_active>;
	pinctrl-1 = <&pwm0_8_pin_sleep>;
	status = "disabled";
};

&pwm0_9 {
	pinctrl-names = "active", "sleep";
	pinctrl-0 = <&pwm0_9_pin_active>;
	pinctrl-1 = <&pwm0_9_pin_sleep>;
	status = "disabled";
};

&pwm0_10 {
	pinctrl-names = "active", "sleep";
	pinctrl-0 = <&pwm0_10_pin_active>;
	pinctrl-1 = <&pwm0_10_pin_sleep>;
	status = "disabled";
};

&pwm0_11 {
	pinctrl-names = "active", "sleep";
	pinctrl-0 = <&pwm0_11_pin_active>;
	pinctrl-1 = <&pwm0_11_pin_sleep>;
	status = "disabled";
};

&pwm0_12 {
	pinctrl-names = "active", "sleep";
	pinctrl-0 = <&pwm0_12_pin_active>;
	pinctrl-1 = <&pwm0_12_pin_sleep>;
	status = "okay";
};

&pwm0_13 {
	pinctrl-names = "active", "sleep";
	pinctrl-0 = <&pwm0_13_pin_active>;
	pinctrl-1 = <&pwm0_13_pin_sleep>;
	status = "okay";
};

&pwm0_14 {
	pinctrl-names = "active", "sleep";
	pinctrl-0 = <&pwm0_14_pin_active>;
	pinctrl-1 = <&pwm0_14_pin_sleep>;
	status = "disabled";
};

&pwm0_15 {
	pinctrl-names = "active", "sleep";
	pinctrl-0 = <&pwm0_15_pin_active>;
	pinctrl-1 = <&pwm0_15_pin_sleep>;
	status = "disabled";
};

&ledc  {
	pinctrl-names = "default", "sleep";
	pinctrl-0 = <&ledc_pins_a>;
	pinctrl-1 = <&ledc_pins_b>;
	led_count = <34>;
	output_mode = "GRB";
	reset_ns = <84>;
	t1h_ns = <800>;
	t1l_ns = <320>;
	t0h_ns = <300>;
	t0l_ns = <800>;
	wait_time0_ns = <84>;
	wait_time1_ns = <84>;
	wait_data_time_ns = <600000>;
	status = "disabled";
};

&irrx {
	pinctrl-names = "default", "sleep";
	pinctrl-0 = <&irrx_pins_default>;
	pinctrl-1 = <&irrx_pins_sleep>;
	status = "okay";
};

&s_irrx {
	pinctrl-names = "default", "sleep";
	pinctrl-0 = <&s_irrx_pins_default>;
	pinctrl-1 = <&s_irrx_pins_sleep>;
	status = "disabled";
};

&irtx {
	pinctrl-names = "default", "sleep";
	pinctrl-0 = <&irtx_pins_default>;
	pinctrl-1 = <&irtx_pins_sleep>;
	status = "disabled";
};

&twi0 {
	clock-frequency = <400000>;
	pinctrl-0 = <&twi0_pins_default>;
	pinctrl-1 = <&twi0_pins_sleep>;
	pinctrl-names = "default", "sleep";
	/* For stability and backwards compatibility, we recommend setting ‘twi_drv_used’ to 1 */
	twi_drv_used = <1>;
	status = "okay";

	eeprom@50 {
		compatible = "atmel,24c16";
		reg = <0x50>;
		status = "okay";
	};
	pcie_usb_phy@74 {
		compatible = "combphy,phy74";
		reg = <0x74>;
		status = "disabled";
	};
	pcie_usb_phy@75 {
		compatible = "combphy,phy75";
		reg = <0x75>;
		status = "disabled";
	};

	//ctp: ctp@0 {
	//	compatible = "allwinner,gslX680";
	//	reg = <0x40>;
	//	device_type = "ctp";
	//	status = "disabled";
	//	ctp_name = "gslX680_3676_1280x800_y83";
	//	ctp_twi_id = <0x0>;
	//	ctp_twi_addr = <0x40>;
	//	ctp_screen_max_x = <0x500>;
	//	ctp_screen_max_y = <0x320>;
	//	ctp_revert_x_flag = <0x0>;
	//	ctp_revert_y_flag = <0x1>;
	//	ctp_exchange_x_y_flag = <0x1>;
	//	ctp_int_port = <&pio PH 9 GPIO_ACTIVE_LOW>;
	//	//ctp_power_io = <&pio PH 14 GPIO_ACTIVE_LOW>;
	//	ctp_wakeup = <&pio PH 10 GPIO_ACTIVE_LOW>;
	//	ctp-supply = <&reg_cldo2>;
	//	ctp_power_ldo_vol = <3300>;
	//};
};

&twi1 {
	clock-frequency = <400000>;
	pinctrl-0 = <&twi1_pins_default>;
	pinctrl-1 = <&twi1_pins_sleep>;
	pinctrl-names = "default", "sleep";
	/* For stability and backwards compatibility, we recommend setting ‘twi_drv_used’ to 1 */
	twi_drv_used = <1>;
	status = "disabled";
        /*DA215S  DA221*/
	//mir3da {
	//	compatible = "allwinner,mir3da";
	//	reg = <0x27>;
	//	device_type = "gsensor";
	//	status = "okay";
	//	gsensor_twi_id = <0x1>;
	//	gsensor_twi_addr = <0x27>;
	//	gsensor_int1 = <&pio PH 11 (GPIO_ACTIVE_LOW | GPIO_PULL_UP)>;
	//	gsensor-supply = <&reg_cldo3>;
	//	gsensor_vcc_io_val = <3300>;
	//};
	///*ms311*/
	//msa {
	//	compatible = "allwinner,msa";
	//	reg = <0x62>;
	//	device_type = "gsensor";
	//	status = "disabled";
	//	gsensor_twi_id = <0x1>;
	//	gsensor_twi_addr = <0x62>;
	//	gsensor_int1 = <&pio PH 11 (GPIO_ACTIVE_LOW | GPIO_PULL_UP)>;
	//	gsensor-supply = <&reg_cldo3>;
	//	gsensor_vcc_io_val = <3300>;
	//};
	//mmc5603 {
	//	compatible = "memsic,mmc5603x";
	//	reg = <0x30>;
	//	status = "okay";
	//	device_type = "magnetormetersensor";
	//	mag_twi_id = <0x1>;
	//	mag_twi_addr = <0x26>;
	//	mag-supply = <&reg_cldo3>;
	//	mag_vcc_io_val = <3300>;
	//};

	//qmi8658 {
	//	compatible = "allwinner,qmi8658";
	//	reg = <0x6b>;
	//	device_type = "gsensor";
	//	status = "okay";
	//	gsensor_twi_id = <0x1>;
	//	gsensor_twi_addr = <0x6b>;
	//	gsensor_int1 = <&pio PL 5 (GPIO_ACTIVE_LOW | GPIO_PULL_UP)>;
	//	gsensor-supply = <&reg_cldo3>;
	//	gsensor_vcc_io_val = <3300>;
	//};
};

&twi3 {
	clock-frequency = <400000>;
	pinctrl-0 = <&twi3_pins_default>;
	pinctrl-1 = <&twi3_pins_sleep>;
	pinctrl-names = "default", "sleep";
	no_suspend = <1>;
	device_type = "twi3";
	status = "okay";
	/* For stability and backwards compatibility, we recommend setting ‘twi_drv_used’ to 1 */
	twi_drv_used = <1>;
	//twi-supply = <&reg_dcdc4>;

	ctp: ctp@0 {
		compatible = "allwinner,goodix";
		reg = <0x14>;
		device_type = "ctp";
		status = "disabled";
		ctp_name = "gt9xxnew_ts";
		ctp_twi_id = <0x3>;
		ctp_twi_addr = <0x14>;
		ctp_screen_max_y = <0x500>;
		ctp_screen_max_x = <0x320>;
		//ctp_revert_x_flag = <0x1>;
		ctp_revert_y_flag = <0x1>;
		ctp_exchange_x_y_flag = <0x1>;
                ctp_int_port = <&pio PE 12 GPIO_ACTIVE_LOW>;
                ctp_wakeup = <&pio PE 11 GPIO_ACTIVE_HIGH>;
		//ctp-supply = <&reg_cldo2>;
		//ctp_power_ldo_vol = <3300>;
	};

	//ctp {
	//	status = "okay";
	//	compatible = "allwinner,goodix";
	//	reg = <0x14>;
	//	device_type = "ctp";
	//	ctp_name = "gt9xxnew_ts";

	//	ctp_twi_id = <0x3>;
	//	ctp_twi_addr = <0x14>;

        //        ctp_screen_max_x = <0x500>;
        //        ctp_screen_max_y = <0x320>;
        //        //ctp_revert_x_flag = <0x0>;
        //        //ctp_revert_y_flag = <0x1>;
        //        //ctp_exchange_x_y_flag = <0x0>;
        //        ctp_int_port = <&pio PE 12 GPIO_ACTIVE_LOW>;
        //        ctp_wakeup = <&pio PE 11 GPIO_ACTIVE_HIGH>;
	//};
};

&twi4 {
	clock-frequency = <400000>;
	pinctrl-0 = <&twi4_pins_default>;
	pinctrl-1 = <&twi4_pins_sleep>;
	pinctrl-names = "default", "sleep";
	/* For stability and backwards compatibility, we recommend setting ‘twi_drv_used’ to 1 */
	twi_drv_used = <1>;
	status = "disabled";
};

&twi5 {
	clock-frequency = <400000>;
	pinctrl-0 = <&twi5_pins_default>;
	pinctrl-1 = <&twi5_pins_sleep>;
	pinctrl-names = "default", "sleep";
	/* For stability and backwards compatibility, we recommend setting ‘twi_drv_used’ to 1 */
	twi_drv_used = <1>;
	status = "disabled";

	//ac107: ac107@36 {
	//	#sound-dai-cells        = <0>;
	//	compatible              = "allwinner,sunxi-ac107";
	//	reg                     = <0x36>;
	//	pllclk-src              = "MCLK";
	//	sysclk-src              = "MCLK";
	//	pcm-bit-first           = "MSB";
	//	frame-sync-width        = <1>;
	//	tx-pin-chmap0           = <0x10101010>;
	//	tx-pin-chmap1           = <0x10101010>;
	//	ch1-dig-vol             = <160>;
	//	ch2-dig-vol             = <160>;
	//	ch1-pga-gain            = <26>;
	//	ch2-pga-gain            = <26>;
	//	status                  = "okay";
	//};
};
&twi6 {
	clock-frequency = <400000>;
	pinctrl-0 = <&s_twi0_pins_default>;
	pinctrl-1 = <&s_twi0_pins_sleep>;
	pinctrl-names = "default", "sleep";
	device_type = "twi6";
	/* For stability and backwards compatibility, we recommend setting ‘twi_drv_used’ to 1 */
	twi_drv_used = <1>;
	no_suspend = <1>;
	status = "okay";

	//tcs0: tcs@41 {
	//	compatible = "ext,tcs4838";
	//	reg = <0x41>;
	//	status = "okay";
	//	tcs4838_delay = <0>;
	//	regulator1: regulators@1 {
	//		reg_tcs0: dcdc0 {
	//			regulator-name = "tcs4838-dcdc0";
	//			regulator-min-microvolt = <712500>;
	//			regulator-max-microvolt = <1500000>;
	//			regulator-ramp-delay = <520>;
	//			regulator-enable-ramp-delay = <1000>;
	//			regulator-always-on;
	//			regulator-boot-on;
	//		};
	//		reg_tcs1: dcdc1 {
	//			regulator-name = "tcs4838-dcdc1";
	//			regulator-min-microvolt = <712500>;
	//			regulator-max-microvolt = <1500000>;
	//			regulator-ramp-delay = <520>;
	//			regulator-enable-ramp-delay = <1000>;
	//		};
	//	};
	//	virtual-ext-dcdc0 {
	//		compatible = "xpower-vregulator,ext-dcdc0";
	//		dcdc0-supply = <&reg_tcs0>;
	//	};
	//	virtual-ext-dcdc1 {
	//		compatible = "xpower-vregulator,ext-dcdc1";
	//		dcdc1-supply = <&reg_tcs1>;
	//	};
	//};

	//sy0: sy@60 {
	//	compatible = "ext,sy8827g";
	//	reg = <0x60>;
	//	status = "okay";
	//	sy8827g_delay = <0>;
	//	regulator2: regulators@2 {
	//		reg_sy0: dcdc0 {
	//			regulator-name = "sy8827g-dcdc0";
	//			regulator-min-microvolt = <712500>;
	//			regulator-max-microvolt = <1500000>;
	//			regulator-ramp-delay = <520>;
	//			regulator-enable-ramp-delay = <1000>;
	//			regulator-always-on;
	//			regulator-boot-on;
	//		};
	//		reg_sy1: dcdc1 {
	//			regulator-name = "sy8827g-dcdc1";
	//			regulator-min-microvolt = <712500>;
	//			regulator-max-microvolt = <1500000>;
	//			regulator-ramp-delay = <520>;
	//			regulator-enable-ramp-delay = <1000>;
	//		};
	//	};
	//	virtual-ext-dcdc0 {
	//		compatible = "xpower-vregulator,ext-dcdc0";
	//		dcdc0-supply = <&reg_sy0>;
	//	};
	//	virtual-ext-dcdc1 {
	//		compatible = "xpower-vregulator,ext-dcdc1";
	//		dcdc1-supply = <&reg_sy1>;
	//	};
	//};

	axp1530: axp1530@36{
		compatible = "ext,axp1530";
		status = "okay";
		reg = <0x36>;

		wakeup-source;

		regulators{
			reg_ext_axp1530_dcdc1: dcdc1 {
				regulator-name = "axp1530-dcdc1";
				regulator-min-microvolt = <500000>;
				regulator-max-microvolt = <3400000>;
				regulator-step-delay-us = <25>;
				regulator-final-delay-us = <50>;
				regulator-always-on;
			};

			reg_ext_axp1530_dcdc2: dcdc2 {
				regulator-name = "axp1530-dcdc2";
				regulator-min-microvolt = <500000>;
				regulator-max-microvolt = <1540000>;
				regulator-step-delay-us = <25>;
				regulator-final-delay-us = <50>;
				regulator-ramp-delay = <200>; /* FIXME */
				regulator-always-on;
			};

			reg_ext_axp1530_dcdc3: dcdc3 {
				regulator-name = "axp1530-dcdc3";
				regulator-min-microvolt = <500000>;
				regulator-max-microvolt = <1840000>;
				regulator-step-delay-us = <25>;
				regulator-final-delay-us = <50>;
				regulator-always-on;
			};

			reg_ext_axp1530_aldo1: ldo1 {
				regulator-name = "axp1530-aldo1";
				regulator-min-microvolt = <500000>;
				regulator-max-microvolt = <3500000>;
				regulator-step-delay-us = <25>;
				regulator-final-delay-us = <50>;
				regulator-boot-on;
				regulator-always-on;
			};

			reg_ext_axp1530_dldo1: ldo2 {
				regulator-name = "axp1530-dldo1";
				regulator-min-microvolt = <500000>;
				regulator-max-microvolt = <3500000>;
				regulator-step-delay-us = <25>;
				regulator-final-delay-us = <50>;
				regulator-boot-on;
				regulator-always-on;
			};
		};
		virtual-ext-dcdc1 {
			compatible = "xpower-vregulator,ext-dcdc1";
			dcdc1-supply = <&reg_ext_axp1530_dcdc1>;
		};
		virtual-ext-dcdc2 {
			compatible = "xpower-vregulator,ext-dcdc2";
			dcdc2-supply = <&reg_ext_axp1530_dcdc2>;
		};
		virtual-ext-dcdc3 {
			compatible = "xpower-vregulator,ext-dcdc3";
			dcdc3-supply = <&reg_ext_axp1530_dcdc3>;
		};
		virtual-ext-aldo1 {
			compatible = "xpower-vregulator,ext-aldo1";
			aldo1-supply = <&reg_ext_axp1530_aldo1>;
		};
		virtual-ext-dldo1 {
			compatible = "xpower-vregulator,ext-dldo1";
			dldo1-supply = <&reg_ext_axp1530_dldo1>;
		};

	};
	pmu0: pmu@35 {
		compatible = "x-powers,axp2202";
		reg = <0x35>;
		status = "okay";
		interrupts = <0 IRQ_TYPE_LEVEL_LOW>;
		interrupt-parent = <&nmi_intc>;
		x-powers,drive-vbus-en;
		pmu_reset = <0>;
		pmu_irq_wakeup = <1>;
		pmu_hot_shutdown = <1>;

		wakeup-source;

		usb_power_supply: usb_power_supply {
			compatible = "x-powers,axp2202-usb-power-supply";
			status = "okay";

			pmu_usbpc_vol = <4600>;
			pmu_usbpc_cur = <500>;
			pmu_usbad_vol = <4000>;
			pmu_usbad_cur = <2500>;
			pmu_usb_typec_used = <0>;
			wakeup_usb_in;
			wakeup_usb_out;
			/* wakeup_typec_in; */
			/* wakeup_typec_out; */

			det_acin_supply = <&gpio_power_supply>;
			pmu_acin_usbid_drv = <&pio PH 12 GPIO_ACTIVE_LOW>;
			pmu_vbus_det_gpio = <&pio PH 13 GPIO_ACTIVE_LOW>;
		};

		gpio_power_supply: gpio_power_supply {
			compatible = "x-powers,gpio-supply";
			status = "disabled";
			pmu_acin_det_gpio = <&pio PH 14 GPIO_ACTIVE_LOW>;
			det_usb_supply = <&usb_power_supply>;
		};

		bat_power_supply: bat-power-supply {
			compatible = "x-powers,axp2202-bat-power-supply";
			param = <&axp2202_parameter>;
			status = "disabled";

			pmu_chg_ic_temp = <0>;

			pmu_battery_rdc= <170>;
			pmu_battery_cap = <5000>;
			pmu_runtime_chgcur = <1000>;
			pmu_suspend_chgcur = <1500>;
			pmu_shutdown_chgcur = <1500>;
			pmu_init_chgvol = <4350>;
			pmu_battery_warning_level1 = <15>;
			pmu_battery_warning_level2 = <0>;
			pmu_chgled_func = <0>;
			pmu_chgled_type = <0>;
			pmu_bat_para1 = <0>;
			pmu_bat_para2 = <0>;
			pmu_bat_para3 = <0>;
			pmu_bat_para4 = <0>;
			pmu_bat_para5 = <0>;
			pmu_bat_para6 = <0>;
			pmu_bat_para7 = <2>;
			pmu_bat_para8 = <3>;
			pmu_bat_para9 = <4>;
			pmu_bat_para10 = <6>;
			pmu_bat_para11 = <9>;
			pmu_bat_para12 = <14>;
			pmu_bat_para13 = <26>;
			pmu_bat_para14 = <38>;
			pmu_bat_para15 = <49>;
			pmu_bat_para16 = <52>;
			pmu_bat_para17 = <56>;
			pmu_bat_para18 = <60>;
			pmu_bat_para19 = <64>;
			pmu_bat_para20 = <70>;
			pmu_bat_para21 = <77>;
			pmu_bat_para22 = <83>;
			pmu_bat_para23 = <87>;
			pmu_bat_para24 = <90>;
			pmu_bat_para25 = <95>;
			pmu_bat_para26 = <99>;
			pmu_bat_para27 = <99>;
			pmu_bat_para28 = <100>;
			pmu_bat_para29 = <100>;
			pmu_bat_para30 = <100>;
			pmu_bat_para31 = <100>;
			pmu_bat_para32 = <100>;

			pmu_bat_temp_enable = <0>;
			pmu_jetia_en        = <0>;
			pmu_bat_charge_ltf = <1695>; //-5
			pmu_bat_charge_htf = <151>; //60
			pmu_bat_shutdown_ltf = <2125>; //-10
			pmu_bat_shutdown_htf = <131>; //65
			pmu_jetia_cool = <1361>; //0
			pmu_jetia_warm = <208>; //50
			pmu_jcool_ifall = <0>;//100%
			pmu_jwarm_ifall = <0>;//100%
			pmu_bat_temp_para1 = <4378>; //Murata -25
			pmu_bat_temp_para2 = <2682>; //-15
			pmu_bat_temp_para3 = <2125>; //-10
			pmu_bat_temp_para4 = <1695>; //-5
			pmu_bat_temp_para5 = <1361>;//0
			pmu_bat_temp_para6 = <1101>; //5
			pmu_bat_temp_para7 = <896>; //10
			pmu_bat_temp_para8 = <604>; //20
			pmu_bat_temp_para9 = <416>; //30
			pmu_bat_temp_para10 = <292>; //40
			pmu_bat_temp_para11 = <246>; //45
			pmu_bat_temp_para12 = <208>; //50
			pmu_bat_temp_para13 = <177>; //55
			pmu_bat_temp_para14 = <151>; //60
			pmu_bat_temp_para15 = <111>; //70
			pmu_bat_temp_para16 = <83>; //80

			wakeup_bat_out;
			/* wakeup_new_soc; */
			/* wakeup_bat_in; */
			/* wakeup_bat_charging; */
			/* wakeup_bat_charge_over; */
			/* wakeup_low_warning1; */
			/* wakeup_low_warning2; */
			wakeup_bat_untemp_work;
			wakeup_bat_ovtemp_work;
			/* wakeup_bat_untemp_chg; */
			/* wakeup_bat_ovtemp_chg; */
		};

		powerkey0: powerkey@0 {
			status = "okay";
			compatible = "x-powers,axp2101-pek";
			pmu_powkey_off_time = <6000>;
			pmu_powkey_off_func = <0>;
			pmu_powkey_off_en = <1>;
			pmu_powkey_long_time = <1500>;
			pmu_powkey_on_time = <512>;
			wakeup_rising;
			wakeup_falling;
		};

		regulator0: regulators@0 {
			reg_dcdc1: dcdc1 {
				regulator-name = "axp2202-dcdc1";
				regulator-min-microvolt = <500000>;
				regulator-max-microvolt = <1540000>;
				regulator-ramp-delay = <250>;
				regulator-enable-ramp-delay = <1000>;
				regulator-boot-on;
				regulator-always-on;
			};
			reg_dcdc2: dcdc2 {
				regulator-name = "axp2202-dcdc2";
				regulator-min-microvolt = <500000>;
				regulator-max-microvolt = <3400000>;
				regulator-ramp-delay = <250>;
				regulator-enable-ramp-delay = <1000>;
				regulator-boot-on;
				regulator-always-on;
			};
			reg_dcdc3: dcdc3 {
				regulator-name = "axp2202-dcdc3";
				regulator-min-microvolt = <500000>;
				regulator-max-microvolt = <1840000>;
				regulator-ramp-delay = <250>;
				regulator-enable-ramp-delay = <1000>;
				regulator-always-on;
			};

			reg_dcdc4: dcdc4 {
				regulator-name = "axp2202-dcdc4";
				regulator-min-microvolt = <1000000>;
				regulator-max-microvolt = <3700000>;
				regulator-ramp-delay = <250>;
				regulator-enable-ramp-delay = <1000>;
				regulator-boot-on;
				regulator-always-on;
			};
			reg_rtcldo: rtcldo {
				/* RTC_LDO is a fixed, always-on regulator */
				regulator-name = "axp2202-rtcldo";
				regulator-min-microvolt = <1800000>;
				regulator-max-microvolt = <1800000>;
				regulator-boot-on;
				regulator-always-on;
			};
			reg_aldo1: aldo1 {
				regulator-name = "axp2202-aldo1";
				regulator-min-microvolt = <500000>;
				regulator-max-microvolt = <3500000>;
				regulator-enable-ramp-delay = <1000>;
				regulator-boot-on;
				regulator-always-on;
			};
			reg_aldo2: aldo2 {
				regulator-name = "axp2202-aldo2";
				regulator-min-microvolt = <500000>;
				regulator-max-microvolt = <3500000>;
				regulator-enable-ramp-delay = <1000>;
				regulator-boot-on;
				regulator-always-on;
			};
			reg_aldo3: aldo3 {
				regulator-name = "axp2202-aldo3";
				regulator-min-microvolt = <500000>;
				regulator-max-microvolt = <3500000>;
				regulator-enable-ramp-delay = <1000>;
				regulator-always-on;
				regulator-boot-on;
			};
			reg_aldo4: aldo4 {
				regulator-name = "axp2202-aldo4";
				regulator-min-microvolt = <500000>;
				regulator-max-microvolt = <3500000>;
				regulator-enable-ramp-delay = <1000>;
				regulator-always-on;
				regulator-boot-on;
			};
			reg_bldo1: bldo1 {
				regulator-name = "axp2202-bldo1";
				regulator-min-microvolt = <500000>;
				regulator-max-microvolt = <3500000>;
				regulator-enable-ramp-delay = <1000>;
				regulator-boot-on;
				regulator-always-on;
			};
			reg_bldo2: bldo2 {
				regulator-name = "axp2202-bldo2";
				regulator-min-microvolt = <500000>;
				regulator-max-microvolt = <3500000>;
				regulator-enable-ramp-delay = <1000>;
				regulator-boot-on;
				regulator-always-on;
			};
			reg_bldo3: bldo3 {
				regulator-name = "axp2202-bldo3";
				regulator-min-microvolt = <500000>;
				regulator-max-microvolt = <3500000>;
				regulator-enable-ramp-delay = <1000>;
				regulator-boot-on;
				regulator-always-on;
			};
			reg_bldo4: bldo4 {
				regulator-name = "axp2202-bldo4";
				regulator-min-microvolt = <500000>;
				regulator-max-microvolt = <3500000>;
				regulator-enable-ramp-delay = <1000>;
				regulator-boot-on;
				regulator-always-on;
			};
			reg_cldo1: cldo1 {
				regulator-name = "axp2202-cldo1";
				regulator-min-microvolt = <500000>;
				regulator-max-microvolt = <3500000>;
				regulator-enable-ramp-delay = <1000>;
				regulator-boot-on;
				regulator-always-on;
			};
			reg_cldo2: cldo2 {
				regulator-name = "axp2202-cldo2";
				regulator-min-microvolt = <500000>;
				regulator-max-microvolt = <3500000>;
				regulator-enable-ramp-delay = <1000>;
				regulator-boot-on;
				regulator-always-on;
			};
			reg_cldo3: cldo3 {
				regulator-name = "axp2202-cldo3";
				regulator-min-microvolt = <500000>;
				regulator-max-microvolt = <3500000>;
				regulator-ramp-delay = <2500>;
				regulator-enable-ramp-delay = <1000>;
				regulator-boot-on;
				regulator-always-on;
			};
			reg_cldo4: cldo4 {
				regulator-name = "axp2202-cldo4";
				regulator-min-microvolt = <500000>;
				regulator-max-microvolt = <3500000>;
				regulator-enable-ramp-delay = <1000>;
				regulator-boot-on;
				regulator-always-on;
			};
			reg_cpusldo: cpusldo {
				/* cpus */
				regulator-name = "axp2202-cpusldo";
				regulator-min-microvolt = <500000>;
				regulator-max-microvolt = <1400000>;
				regulator-boot-on;
				regulator-always-on;
			};
			reg_vmid: vmid {
				regulator-name = "axp2202-vmid";
				regulator-enable-ramp-delay = <1000>;
			};
			reg_drivevbus: drivevbus {
				regulator-name = "axp2202-drivevbus";
				regulator-enable-ramp-delay = <1000>;
				drivevbusin-supply = <&reg_vmid>;
			};
		};

		virtual-dcdc1 {
			compatible = "xpower-vregulator,dcdc1";
			dcdc1-supply = <&reg_dcdc1>;
		};
		virtual-dcdc2 {
			compatible = "xpower-vregulator,dcdc2";
			dcdc2-supply = <&reg_dcdc2>;
		};
		virtual-dcdc3 {
			compatible = "xpower-vregulator,dcdc3";
			dcdc3-supply = <&reg_dcdc3>;
		};
		virtual-dcdc4 {
			compatible = "xpower-vregulator,dcdc4";
			dcdc4-supply = <&reg_dcdc4>;
		};
		virtual-rtcldo {
			compatible = "xpower-vregulator,rtcldo";
			rtcldo-supply = <&reg_rtcldo>;
		};
		virtual-aldo1 {
			compatible = "xpower-vregulator,aldo1";
			aldo1-supply = <&reg_aldo1>;
		};
		virtual-aldo2 {
			compatible = "xpower-vregulator,aldo2";
			aldo2-supply = <&reg_aldo2>;
		};
		virtual-aldo3 {
			compatible = "xpower-vregulator,aldo3";
			aldo3-supply = <&reg_aldo3>;
		};
		virtual-aldo4 {
			compatible = "xpower-vregulator,aldo4";
			aldo4-supply = <&reg_aldo4>;
		};
		virtual-bldo1 {
			compatible = "xpower-vregulator,bldo1";
			bldo1-supply = <&reg_bldo1>;
		};
		virtual-bldo2 {
			compatible = "xpower-vregulator,bldo2";
			bldo2-supply = <&reg_bldo2>;
		};
		virtual-bldo3 {
			compatible = "xpower-vregulator,bldo3";
			bldo3-supply = <&reg_bldo3>;
		};
		virtual-bldo4 {
			compatible = "xpower-vregulator,bldo4";
			bldo4-supply = <&reg_bldo4>;
		};
		virtual-cldo1 {
			compatible = "xpower-vregulator,cldo1";
			cldo1-supply = <&reg_cldo1>;
		};
		virtual-cldo2 {
			compatible = "xpower-vregulator,cldo2";
			cldo2-supply = <&reg_cldo2>;
		};
		virtual-cldo3 {
			compatible = "xpower-vregulator,cldo3";
			cldo3-supply = <&reg_cldo3>;
		};
		virtual-cldo4 {
			compatible = "xpower-vregulator,cldo4";
			cldo4-supply = <&reg_cldo4>;
		};
		virtual-cpusldo {
			compatible = "xpower-vregulator,cpusldo";
			cpusldo-supply = <&reg_cpusldo>;
		};
		virtual-drivevbus {
			compatible = "xpower-vregulator,drivevbus";
			drivevbus-supply = <&reg_drivevbus>;
		};
		axp_gpio0: axp_gpio@0 {
			gpio-controller;
			#size-cells = <0>;
			#gpio-cells = <6>;
			status = "okay";
		};
	};
};

/{
	axp2202_parameter:axp2202-parameter {
		select = "battery-model";

		battery-model {
			parameter = /bits/ 8 <0x01 0xf5 0x40 0x00 0x1b 0x1e 0x28 0x0f
				0x0c 0x1e 0x32 0x02 0x14 0x05 0x0a 0x04
				0x74 0xfb 0xc8 0x0d 0x43 0x10 0xcc 0xfb
				0x46 0x01 0xea 0x14 0x10 0x06 0xcc 0x06
				0x9d 0x0b 0x63 0x0f 0xf4 0x0f 0x94 0x0a
				0x4f 0x0e 0xf4 0x0e 0xeb 0x04 0xdd 0x04
				0xd1 0x09 0xc7 0x0e 0xb9 0x0e 0xb6 0x09
				0xae 0x0e 0x97 0x0e 0x97 0x04 0x86 0x04
				0x73 0x09 0x69 0x0e 0x60 0x0e 0x1e 0x08
				0x21 0x58 0x28 0x22 0x18 0x06 0x0d 0x01
				0xc5 0x98 0x7e 0x66 0x4e 0x44 0x38 0x1a
				0x12 0x0a 0xf6 0x00 0x00 0xf6 0x00 0xf6
				0x00 0xfb 0x00 0x00 0xfb 0x00 0x00 0xfb
				0x00 0x00 0xf6 0x00 0x00 0xf6 0x00 0xf6
				0x00 0xfb 0x00 0x00 0xfb 0x00 0x00 0xfb
				0x00 0x00 0xf6 0x00 0x00 0xf6 0x00 0xf6>;
		};
	};
};

&nand0 {
	compatible = "allwinner,sun55iw3-nand";
	device_type = "nand0";
	//reg = <0x0 0x04011000 0x0 0x1000>;/* nand0 */
	pinctrl-names = "default", "sleep";
	pinctrl-0 = <&nand0_pins_default &nand0_pins_rb>;
	pinctrl-1 = <&nand0_pins_sleep>;
	nand0_regulator1 = "vcc-nand";
	nand0_regulator2 = "none";
	nand0_cache_level = <0x55aaaa55>;
	nand0_flush_cache_num = <0x55aaaa55>;
	nand0_capacity_level = <0x55aaaa55>;
	nand0_id_number_ctl = <0x55aaaa55>;
	nand0_print_level = <0x55aaaa55>;
	nand0_p0 = <0x55aaaa55>;
	nand0_p1 = <0x55aaaa55>;
	nand0_p2 = <0x55aaaa55>;
	nand0_p3 = <0x55aaaa55>;
	chip_code = "sun55iw3";
	status = "disabled";
};

&sdc2 {
	non-removable;
	bus-width = <8>;
	mmc-ddr-1_8v;
	mmc-hs200-1_8v;
	mmc-hs400-1_8v;
	no-sdio;
	no-sd;
	ctl-spec-caps = <0x328>;
	cap-mmc-highspeed;
	sunxi-power-save-mode;
	sunxi-dis-signal-vol-sw;
	mmc-bootpart-noacc;
	/*cap-hsq;*/
	cqe-on;
	ctl-cmdq-md = <0x2>;
	max-frequency = <100000000>;
	vmmc-supply = <&reg_cldo3>;
	/*emmc io vol 3.3v*/
	/*vqmmc-supply = <&reg_aldo1>;*/
	/*emmc io vol 1.8v*/
	vqmmc-supply = <&reg_cldo1>;
	status = "okay";
	sdc_tm4_sm0_freq0 = <0xffffffff>;
	sdc_tm4_sm0_freq1 = <0xffffffff>;
	sdc_tm4_sm1_freq0 = <0xff20ffff>;
	sdc_tm4_sm1_freq1 = <0xffffffff>;
	sdc_tm4_sm2_freq0 = <0xff2020ff>;
	sdc_tm4_sm2_freq1 = <0xffffffff>;
	sdc_tm4_sm3_freq0 = <0x2020ffff>;
	sdc_tm4_sm3_freq1 = <0xffff2e26>;
	sdc_tm4_sm4_freq0 = <0x1421ffff>;
	sdc_tm4_sm4_freq1 = <0xffff090e>;
	sdc_tm4_sm4_freq0_cmd = <0x2020ffff>;
	sdc_tm4_sm4_freq1_cmd = <0xffff2e27>;
};

&sdc0 {
	bus-width = <4>;
	cd-gpios = <&pio PF 6 (GPIO_ACTIVE_LOW | GPIO_PULL_UP)>;
	/*non-removable;*/
	/*broken-cd;*/
	/*cd-inverted*/
	/*data3-detect;*/
	/*card-pwr-gpios = <&pio PH 14 1 1 2 0xffffffff>;*/
	cd-used-24M;
	cd-set-debounce = <0x1>;
	cap-sd-highspeed;
	sd-uhs-sdr50;
	sd-uhs-ddr50;
	sd-uhs-sdr104;
	no-sdio;
	no-mmc;
	sunxi-power-save-mode;
	/*sunxi-dis-signal-vol-sw;*/
	max-frequency = <150000000>;
	ctl-spec-caps = <0x428>;
	vmmc-supply = <&reg_cldo3>;
	vqmmc33sw-supply = <&reg_cldo3>;
	vdmmc33sw-supply = <&reg_cldo3>;
	vqmmc18sw-supply = <&reg_cldo1>;
	vdmmc18sw-supply = <&reg_cldo1>;
	status = "okay";
};


&sdc1 {
	bus-width = <4>;
	no-mmc;
	no-sd;
	cap-sd-highspeed;
	/*sd-uhs-sdr12*/
	sd-uhs-sdr25;
	sd-uhs-sdr50;
	sd-uhs-ddr50;
	sd-uhs-sdr104;
	/*sunxi-power-save-mode;*/
	sunxi-dis-signal-vol-sw;
	cap-sdio-irq;
	keep-power-in-suspend;
	ignore-pm-notify;
	max-frequency = <208000000>;
	ctl-spec-caps = <0x428>;
	status = "okay";
};

&rfkill {
	compatible = "allwinner,sunxi-rfkill";
	chip_en;
	power_en;
	pinctrl-0;
	pinctrl-names;
	status = "okay";

	/* wlan session */
	wlan {
		compatible    = "allwinner,sunxi-wlan";
		clocks        = <&rtc_ccu CLK_OSC32K_OUT>;
		clock-names   = "osc32k-out";
		wlan_power    = "axp2202-aldo3", "axp2202-bldo1", "axp2202-bldo2"; /* vcc-pl/vcc-pg/vcc-pm */
		wlan_power_vol= <3300000>, <1800000>, <1800000>;
		wlan_busnum   = <0x1>;
		wlan_regon    = <&r_pio PM 1 GPIO_ACTIVE_HIGH>;
		wlan_hostwake = <&r_pio PM 0 GPIO_ACTIVE_HIGH>;
		wakeup-source;
	};

	/* bt session */
	bt {
		compatible    = "allwinner,sunxi-bt";
		clocks        = <&rtc_ccu CLK_OSC32K_OUT>;
		clock-names   = "osc32k-out";
		bt_power    = "axp2202-aldo3", "axp2202-bldo1", "axp2202-bldo2"; /* vcc-pl/vcc-pg/vcc-pm */
		bt_power_vol= <3300000>, <1800000>, <1800000>;
		bt_rst_n      = <&r_pio PM 2 GPIO_ACTIVE_LOW>;
	};
};

&addr_mgt {
	compatible     = "allwinner,sunxi-addr_mgt";
	type_addr_wifi = <0x0>;
	type_addr_bt   = <0x0>;
	type_addr_eth  = <0x0>;
	status         = "okay";
};

&btlpm {
	compatible  = "allwinner,sunxi-btlpm";
	uart_index  = <0x1>;
	bt_wake     = <&r_pio PM 3 GPIO_ACTIVE_HIGH>;
	bt_hostwake = <&r_pio PM 4 GPIO_ACTIVE_HIGH>;
	wakeup-source;
	status      = "okay";
};

/*
 *usb_port_type: usb mode. 0-device, 1-host, 2-otg.
 *usb_detect_type: usb hotplug detect mode. 0-none, 1-vbus/id detect, 2-id/dpdm detect.
 *usb_detect_mode: 0-thread scan, 1-id gpio interrupt, 2-pmu notify.
 *usb_id_gpio: gpio for id detect.
 *usb_det_vbus_gpio: gpio for id detect. gpio or "axp_ctrl";
 *usb_wakeup_suspend：0-SUPER_STANDBY, 1-USB_STANDBY.
 */
&usbc0 {
	device_type = "usbc0";
	usb_port_type = <0x2>;
	usb_detect_type = <0x2>;
	usb_detect_mode = <0x0>;
	usb_id_gpio;
	usb_det_vbus_gpio = "axp_ctrl";
	det_vbus_supply = <&usb_power_supply>;
	usb_regulator_io = "nocare";
	usb_wakeup_suspend = <1>;
	usb_luns = <3>;
	usb_serial_unique = <0>;
	usb_serial_number = "20080411";
	rndis_wceis = <1>;
	wakeup-source;
	status = "okay";
};

&udc {
	det_vbus_supply = <&usb_power_supply>;
	status = "okay";
};

&ehci0 {
	drvvbus-supply = <&reg_drivevbus>;
	status = "okay";
};

&ohci0 {
	drvvbus-supply = <&reg_drivevbus>;
	status = "okay";
};

&usbc1 {
	device_type = "usbc1";
	usb_regulator_io = "nocare";
	usb_wakeup_suspend = <1>;
	wakeup-source;
	status = "okay";
};

&ehci1 {
	drvvbus-supply = <&reg_usb1_vbus>;
	status = "okay";
};

&ohci1 {
	drvvbus-supply = <&reg_usb1_vbus>;
	status = "okay";
};

//&usbc2 {
//        device_type = "usbc2";
//        drvvbus-supply = <&reg_drivevbus>;
//        status = "okay";
//};
//
//&u2phy {
//        status = "okay";
//};
//
//&xhci2 {
//	dr_mode = "host";
//	status = "okay";
//};


/*
 * clk-freq-24M : use Internal 24M reference clock
 * clk-freq-100M: use Internal 100M reference clock
 *
 * Pick one of two.
 */
&combophy {
	clk-freq-100M;
	phy_use_sel = <0>; /* 0:PCIE; 1:USB3 */
	status = "okay";
};

//&combophy {
//        resets = <&ccu RST_BUS_PCIE_USB3>;
//        phy_use_sel = <1>; /* 0:PCIE; 1:USB3 */
//        status = "okay";
//};


&pcie {
	reset-gpios = <&pio PH 11 GPIO_ACTIVE_HIGH>;
	wake-gpios = <&pio PH 12 GPIO_ACTIVE_HIGH>;
	clk-freq-100M;
	status = "okay";
};

&gpu {
	gpu_idle = <1>;
	dvfs_status = <1>;
	mali-supply = <&reg_dcdc2>;
};

/*----------------------------------------------------------------------------------
disp init configuration

disp_mode             (0:screen0<screen0,fb0>)
screenx_output_type   (0:none; 1:lcd; 2:tv; 3:hdmi;5:vdpo)
screenx_output_mode   (used for hdmi output, 0:480i 1:576i 2:480p 3:576p 4:720p50)
                      (5:720p60 6:1080i50 7:1080i60 8:1080p24 9:1080p50 10:1080p60)
screenx_output_format (for hdmi, 0:RGB 1:yuv444 2:yuv422 3:yuv420)
screenx_output_bits   (for hdmi, 0:8bit 1:10bit 2:12bit 2:16bit)
screenx_output_eotf   (for hdmi, 0:reserve 4:SDR 16:HDR10 18:HLG)
screenx_output_cs     (for hdmi, 0:undefined  257:BT709 260:BT601  263:BT2020)
screenx_output_dvi_hdmi (for hdmi, 0:undefined 1:dvi mode 2:hdmi mode)
screen0_output_range   (for hdmi, 0:default 1:full 2:limited)
screen0_output_scan    (for hdmi, 0:no data 1:overscan 2:underscan)
screen0_output_aspect_ratio  (for hdmi, 8-same as original picture 9-4:3 10-16:9 11-14:9)
fbx format            (4:RGB655 5:RGB565 6:RGB556 7:ARGB1555 8:RGBA5551 9:RGB888 10:ARGB8888 12:ARGB4444)
fbx pixel sequence    (0:ARGB 1:BGRA 2:ABGR 3:RGBA)
fb0_scaler_mode_enable(scaler mode enable, used FE)
fbx_width,fbx_height  (framebuffer horizontal/vertical pixels, fix to output resolution while equal 0)
lcdx_backlight        (lcd init backlight,the range:[0,256],default:197
lcdx_yy               (lcd init screen bright/contrast/saturation/hue, value:0~100, default:50/50/57/50)
lcd0_contrast         (LCD contrast, 0~100)
lcd0_saturation       (LCD saturation, 0~100)
lcd0_hue              (LCD hue, 0~100)
framebuffer software rotation setting:
disp_rotation_used:   (0:disable; 1:enable,you must set fbX_width to lcd_y,
set fbX_height to lcd_x)
degreeX:              (X:screen index; 0:0 degree; 1:90 degree; 3:270 degree)
degreeX_Y:            (X:screen index; Y:layer index 0~15; 0:0 degree; 1:90 degree; 3:270 degree)
devX_output_type : config output type in bootGUI framework in UBOOT-2018.
				   (0:none; 1:lcd; 2:tv; 4:hdmi;)
devX_output_mode : config output resolution(see include/video/sunxi_display2.h) of bootGUI framework in UBOOT-2018
devX_screen_id   : config display index of bootGUI framework in UBOOT-2018
devX_do_hpd      : whether do hpd detectation or not in UBOOT-2018
chn_cfg_mode     : Hardware DE channel allocation config. 0:single display with 6
				   channel, 1:dual display with 4 channel in main display and 2 channel in second
                   display, 2:dual display with 3 channel in main display and 3 channel in second
                   in display.
----------------------------------------------------------------------------------*/

//&disp {
//	disp_init_enable         = <1>;
//	disp_mode                = <0>;
//
//	screen0_output_type      = <1>;
//	screen0_output_mode      = <4>;
//	screen0_to_lcd_index     = <1>;
//
//	screen1_output_type      = <3>;
//	screen1_output_mode      = <10>;
//
//	screen1_output_format    = <0>;
//	screen1_output_bits      = <0>;
//	screen1_output_eotf      = <4>;
//	screen1_output_cs        = <257>;
//	screen1_output_dvi_hdmi  = <2>;
//	screen1_output_range     = <2>;
//	screen1_output_scan      = <0>;
//	screen1_output_aspect_ratio = <8>;
//	screen1_to_lcd_index     = <2>;
//
//	dev0_output_type         = <1>;
//	dev0_output_mode         = <4>;
//	dev0_screen_id           = <0>;
//	dev0_do_hpd              = <0>;
//
//	dev1_output_type         = <4>;
//	dev1_output_mode         = <10>;
//	dev1_screen_id           = <1>;
//	dev1_do_hpd              = <1>;
//
//	def_output_dev           = <0>;
//	hdmi_mode_check          = <1>;
//
//	fb_format                = <0>;
//	fb_num                   = <1>;
//	fb_debug                 = <1>;
//	/*<disp channel layer zorder>*/
//	fb0_map                  = <0 1 0 16>;
//	fb0_width                = <800>;
//	fb0_height               = <1280>;
//	/*<disp channel layer zorder>*/
//	fb1_map                  = <0 2 0 16>;
//	fb1_width                = <300>;
//	fb1_height               = <300>;
//	/*<disp channel layer zorder>*/
//	fb2_map                  = <1 0 0 16>;
//	fb2_width                = <1280>;
//	fb2_height               = <720>;
//	/*<disp channel layer zorder>*/
//	fb3_map                  = <1 1 0 16>;
//	fb3_width                = <300>;
//	fb3_height               = <300>;
//
//	chn_cfg_mode             = <3>;
//	disp_para_zone           = <1>;
//
//	//pwms = <&pwm0 0 5000000 0>;
//	//pwm-names = "backlight";
//	/* VCC-LCD*/
//	/* dc1sw-supply = <&reg_dc1sw>; */
//	/* VCC-DSI */
//	/* eldo3-supply = <&reg_eldo3>; */
//	/* VCC-PD */
//	/* dcdc1-supply = <&reg_dcdc1>; */
//
//	cldo4-supply = <&reg_cldo4>;
//	cldo1-supply = <&reg_cldo1>;
//
//	//pinctrl-names = "active", "sleep";
//	//pinctrl-0 = <&pwm0_0_pin_active>;
//	//pinctrl-1 = <&pwm0_0_pin_sleep>;
//};

&lcd0 {
	lcd_used            = <1>;
	status              = "okay";
	lcd_driver_name     = "SQ101D_Q5DI404_84H501";
	lcd_backlight       = <50>;
	lcd_if              = <4>;

	lcd_x               = <1200>;
	lcd_y               = <1920>;
	lcd_width           = <136>;
	lcd_height          = <217>;
	lcd_dclk_freq       = <157>;

	lcd_pwm_used        = <0>;
	lcd_pwm_ch          = <7>;
	lcd_pwm_freq        = <50000>;
	lcd_pwm_pol         = <0>;
	lcd_pwm_max_limit   = <255>;

	lcd_hbp             = <50>;
	lcd_ht              = <1330>;
	lcd_hspw            = <10>;
	lcd_vbp             = <20>;
	lcd_vt              = <1960>;
	lcd_vspw            = <4>;

	lcd_frm             = <0>;
	lcd_gamma_en        = <0>;
	lcd_bright_curve_en = <0>;
	lcd_cmap_en         = <0>;

	deu_mode            = <0>;
	lcdgamma4iep        = <22>;
	smart_color         = <90>;

	lcd_dsi_if          = <0>;
	lcd_dsi_lane        = <4>;
	lcd_dsi_format      = <0>;
	lcd_dsi_te          = <0>;
	lcd_dsi_eotp        = <0>;

	lcd_power1 = "cldo4";
	lcd_power2 = "cldo1";

	lcd_gpio_2 = <&pio PD 22 GPIO_ACTIVE_HIGH>; //reset

	pinctrl-0 = <&dsi0_4lane_pins_a>;
	pinctrl-1 = <&dsi0_4lane_pins_b>;

	//lcd_bl_en = <&pio PH 18 GPIO_ACTIVE_HIGH>;
	lcd_bl_0_percent	= <5>;
	#if defined(SKTL_LCD_10)
	lcd_bl_100_percent  = <75>;
	#else
	lcd_bl_100_percent  = <90>;
	#endif
};

#if 0
&lcd1 {
	lcd_used            = <1>;
	status              = "okay";
	lcd_driver_name     = "SQ101D_Q5DI404_84H501";
	lcd_backlight       = <50>;
	lcd_if              = <4>;

	lcd_x               = <800>;
	lcd_y               = <1280>;
	lcd_width           = <136>;
	lcd_height          = <217>;
	lcd_dclk_freq       = <71>;

	lcd_pwm_used        = <1>;
	lcd_pwm_ch          = <0>;
	lcd_pwm_freq        = <50000>;
	lcd_pwm_pol         = <0>;
	lcd_pwm_max_limit   = <255>;

	lcd_hbp         = <56>;
	lcd_ht          = <908>;
	lcd_hspw        = <8>;
	lcd_vbp         = <21>;
	lcd_vt          = <1317>;
	lcd_vspw        = <6>;

	lcd_frm             = <0>;
	lcd_gamma_en        = <0>;
	lcd_bright_curve_en = <0>;
	lcd_cmap_en         = <0>;
	lcd_start_delay     = <2>;

	deu_mode            = <0>;
	lcdgamma4iep        = <22>;
	smart_color         = <90>;

	lcd_dsi_if          = <0>;
	lcd_dsi_lane        = <4>;
	lcd_dsi_format      = <0>;
	lcd_dsi_te          = <0>;
	lcd_dsi_eotp        = <0>;

	lcd_power1 = "cldo4";
	lcd_power2 = "cldo1";

	lcd_gpio_2 = <&pio PD 22 GPIO_ACTIVE_HIGH>; //reset

	pinctrl-0 = <&dsi1_4lane_pins_a>;
	pinctrl-1 = <&dsi1_4lane_pins_b>;

	lcd_bl_en = <&pio PH 18 GPIO_ACTIVE_HIGH>;
	lcd_bl_0_percent	= <5>;
	#if defined(SKTL_LCD_10)
	lcd_bl_100_percent  = <75>;
	#else
	lcd_bl_100_percent  = <90>;
	#endif
};
#else

&lcd1 {
	lcd_used            = <1>;

	lcd_driver_name     = "CC10132007_40A";
	lcd_backlight       = <50>;
	lcd_if              = <4>;

	lcd_x               = <800>;
	lcd_y               = <1280>;
	lcd_width           = <135>;
	lcd_height          = <216>;
	lcd_dclk_freq       = <68>;

	lcd_pwm_used        = <1>;
	lcd_pwm_ch          = <0>;
	lcd_pwm_freq        = <50000>;
	lcd_pwm_pol         = <0>;
	lcd_pwm_max_limit   = <255>;
	lcd_pwm_name        = "backlight";

	lcd_hbp             = <40>;
	lcd_ht              = <860>;
	lcd_hspw            = <20>;
	lcd_vbp             = <12>;
	lcd_vt              = <1322>;
	lcd_vspw            = <4>;

	lcd_frm             = <0>;
	lcd_gamma_en        = <0>;
	lcd_bright_curve_en = <0>;
	lcd_cmap_en         = <0>;
	lcd_start_delay     = <1>;

	lcd_dsi_if          = <0>;
	lcd_dsi_lane        = <4>;
	lcd_dsi_format      = <0>;
	lcd_dsi_te          = <0>;
	lcd_dsi_eotp        = <0>;

	deu_mode            = <0>;
	lcdgamma4iep        = <22>;
	smart_color         = <90>;

	lcd_power1 = "cldo4";
	lcd_power2 = "cldo1";

	lcd_gpio_2 = <&pio PD 22 GPIO_ACTIVE_HIGH>; //reset

	pinctrl-0 = <&dsi1_4lane_pins_a>;
	pinctrl-1 = <&dsi1_4lane_pins_b>;

	lcd_bl_en = <&pio PH 18 GPIO_ACTIVE_HIGH>;
	lcd_bl_0_percent	= <5>;

};
#endif

&lcd2 {
	lcd_used            = <1>;

	lcd_driver_name     = "default_lcd";
	lcd_backlight       = <50>;
	lcd_if              = <0>;

	lcd_x               = <800>;
	lcd_y               = <480>;
	lcd_width           = <150>;
	lcd_height          = <94>;
	lcd_dclk_freq       = <48>;

	lcd_pwm_used        = <1>;
	lcd_pwm_ch          = <7>;
	lcd_pwm_freq        = <50000>;
	lcd_pwm_pol         = <0>;

	lcd_hbp             = <55>;
	lcd_ht              = <1240>;
	lcd_hspw            = <20>;
	lcd_vbp             = <35>;
	lcd_vt              = <650>;
	lcd_vspw            = <10>;

	lcd_lvds_if         = <0>;
	lcd_lvds_colordepth = <1>;
	lcd_lvds_mode       = <0>;
	lcd_frm             = <1>;
	lcd_io_phase        = <0x0000>;
	lcd_gamma_en        = <0>;
	lcd_bright_curve_en = <0>;
	lcd_cmap_en         = <0>;

	deu_mode            = <0>;
	lcdgamma4iep        = <22>;
	smart_color         = <90>;

	pinctrl-0 = <&rgb24_pins_a>;
	pinctrl-1 = <&rgb24_pins_b>;
};

/*lvds*/
/*&lcd0 {
    lcd_used            = <1>;

    lcd_driver_name     = "default_lcd";
    lcd_backlight       = <50>;
    lcd_if              = <3>;
    lcd_x               = <1024>;
    lcd_y               = <600>;
    lcd_width           = <223>;
    lcd_height          = <125>;
    lcd_dclk_freq       = <51>;
    lcd_pwm_used        = <1>;
    lcd_pwm_ch          = <0>;
    lcd_pwm_freq        = <50000>;
    lcd_pwm_pol         = <0>;
    lcd_pwm_max_limit   = <255>;
    lcd_hbp             = <20>;
    lcd_ht              = <1344>;
    lcd_hspw            = <10>;
    lcd_vbp             = <20>;
    lcd_vt              = <635>;
    lcd_vspw            = <10>;
    lcd_lvds_if         = <0>;
    lcd_lvds_colordepth = <0>;
    lcd_lvds_mode       = <0>;
    lcd_frm             = <0>;
    lcd_hv_clk_phase    = <0>;
    lcd_hv_sync_polarity= <0>;
    lcd_gamma_en        = <0>;
    lcd_bright_curve_en = <0>;
    lcd_cmap_en         = <0>;

    deu_mode            = <0>;
    lcdgamma4iep        = <22>;
    smart_color         = <90>;
    pinctrl-0 = <&lvds0_pins_a>;
    pinctrl-1 = <&lvds0_pins_b>;
};*/

&hdmi {
	hdmi_used = <1>;
	cldo1-supply = <&reg_cldo1>;
	hdmi_power0 = "cldo1";
	vmid-supply = <&reg_vmid>;
	hdmi_power1 = "vmid";
	hdmi_power_cnt = <2>;
	hdmi_hdcp_enable = <1>;
	hdmi_hdcp22_enable = <0>;
	hdmi_cts_compatibility = <0>;
	hdmi_cec_support = <1>;
	hdmi_cec_super_standby = <1>;
	hdmi_skip_bootedid = <1>;

	ddc_en_io_ctrl = <0>;
	power_io_ctrl = <0>;

	status = "okay";
};

&cpu0 {
	cpu-supply = <&reg_dcdc1>;
};

&cpu4 {
	cpu-supply = <&reg_ext_axp1530_dcdc1>;
};

&npu {
	npu-supply = <&reg_ext_axp1530_dcdc3>;
	status = "okay";
};

&dsufreq {
	dsu-supply = <&reg_dcdc1>;
};

&ve {
	ve-supply = <&reg_dcdc2>;
};

/* audio dirver module -> audio codec */
&codec {
	//tx-hub-en;
	//rx-sync-en;

	dac-vol		= <63>;		/* default value:63 range:0->63 */
	dacl-vol	= <160>;	/* default value:160 range:0->255 */
	dacr-vol	= <160>;	/* default value:160 range:0->255 */
	adc1-vol	= <160>;	/* default value:160 range:0->255 */
	adc2-vol	= <160>;	/* default value:160 range:0->255 */
	adc3-vol	= <160>;	/* default value:160 range:0->255 */
	lineout-gain	= <31>;		/* default value:31 range:0->31 */
	hpout-gain	= <7>;		/* default value:7 range:0->7 */
	adc1-gain	= <31>;		/* default value:31 range:0->31 */
	adc2-gain	= <31>;		/* default value:31 range:0->31 */
	adc3-gain	= <31>;		/* default value:31 range:0->31 */

	/* to do: avcc-1.8 vdd33-3.3 cpvin-1.8 */
	avcc-external;
	avcc-supply	= <&reg_aldo4>;
	avcc-vol	= <1800000>;
	vdd-external;
	vdd-supply	= <&reg_cldo3>;
	vdd-vol		= <3300000>;
	cpvin-external;
	cpvin-supply	= <&reg_cldo1>;
	cpvin-vol	= <1800000>;

	pa-pin-max	= <1>;
	pa-pin-0	= <&pio PH 6 GPIO_ACTIVE_HIGH>;
	pa-pin-level-0	= <1>;
	pa-pin-msleep-0	= <0>;

	jack-det-level		= <1>;
	jack-det-threshold	= <8>;
	jack-det-debouce	= <0>; /* optional value range:0->15 */

	status = "okay";
};

&codec_plat {
	status = "okay";
};

&codec_mach {
	soundcard-mach,jack-support = <1>;
	status = "okay";
	soundcard-mach,cpu {
		sound-dai = <&codec_plat>;
	};
	soundcard-mach,codec {
		sound-dai = <&codec>;
	};
};

&hdmi_codec {
	extcon = <&hdmi>;
	status = "okay";
};

/* audio dirver module -> owa */
&owa_plat {
	pinctrl-used;
	pinctrl-names	= "default","sleep";
	pinctrl-0	= <&owa_pins_a>;
	pinctrl-1	= <&owa_pins_b>;
	tx-hub-en;
	status		= "okay";
};

&owa_mach {
	status		= "okay";
	soundcard-mach,cpu {
		sound-dai = <&owa_plat>;
	};
	soundcard-mach,codec {
	};
};

/* audio dirver module -> DMIC */
&dmic_plat {
	rx-chmap	= <0x76543210>;
	data-vol	= <0xB0>;
	rxdelaytime	= <0>;
	/* pinctrl-used; */
	/* pinctrl-names	= "default","sleep"; */
	/* pinctrl-0	= <&dmic_pins_a>; */
	/* pinctrl-1	= <&dmic_pins_b>; */
	rx-sync-en;
	status		= "disabled";
};

&dmic_mach {
	status		= "disabled";
	soundcard-mach,cpu {
		sound-dai = <&dmic_plat>;
	};
	soundcard-mach,codec {
	};
};

/* audio dirver module -> I2S/PCM */
//&i2s0_plat {
//	tdm-num		= <0>;
//	tx-pin		= <0>;
//	rx-pin		= <0>;
//	pinctrl-used;
//	pinctrl-names	= "default","sleep";
//	pinctrl-0	= <&i2s0_pins_a>;
//	pinctrl-1	= <&i2s0_pins_b>;
//	tx-hub-en;
//	rx-sync-en;
//	status		= "disabled";
//};
//
//&i2s0_mach {
//	soundcard-mach,format		= "i2s";
//	soundcard-mach,frame-master	= <&i2s0_cpu>;
//	soundcard-mach,bitclock-master	= <&i2s0_cpu>;
//	/* soundcard-mach,frame-inversion; */
//	/* soundcard-mach,bitclock-inversion; */
//	soundcard-mach,slot-num		= <2>;
//	soundcard-mach,slot-width	= <32>;
//	soundcard-mach,capture-only;
//	status		= "disabled";
//	i2s0_cpu: soundcard-mach,cpu {
//		sound-dai = <&i2s0_plat>;
//		/* note: pll freq = 24.576M or 22.5792M * pll-fs */
//		soundcard-mach,pll-fs	= <1>;
//		/* note:
//		 * mclk freq = mclk-fs * 12.288M or 11.2896M	(when mclk-fp ture)
//		 * mclk freq = mclk-fs * pcm rate		(when mclk-fp false)
//		 */
//		soundcard-mach,mclk-fp;
//		soundcard-mach,mclk-fs	= <1>;
//	};
//	i2s0_codec: soundcard-mach,codec {
//		sound-dai               = <&ac107>;
//		soundcard-mach,pll-fs   = <1>;
//	};
//};

&i2s1_plat {
	tdm-num		= <1>;
	tx-pin		= <0>;
	tx-pin0-map0	= <0x76543210>;
	tx-pin0-map1	= <0xFEDCBA98>;
	rx-pin		= <0>;
	pinctrl-used;
	pinctrl-names= "default","sleep";
	pinctrl-0	= <&i2s1_pins_a &i2s1_pins_c &i2s1_pins_d>;
	pinctrl-1	= <&i2s1_pins_b>;
	tx-hub-en;
	rx-sync-en;
	status		= "okay";
};

&i2s1_mach {
	soundcard-mach,format		= "dsp_a";
	soundcard-mach,frame-master	= <&i2s1_cpu>;
	soundcard-mach,bitclock-master	= <&i2s1_cpu>;
	/* soundcard-mach,frame-inversion; */
	soundcard-mach,bitclock-inversion;
	soundcard-mach,slot-num		= <2>;
	soundcard-mach,slot-width	= <32>;
	status		= "okay";
	i2s1_cpu: soundcard-mach,cpu {
		sound-dai = <&i2s1_plat>;
		soundcard-mach,pll-fs	= <1>;
		soundcard-mach,mclk-fs	= <0>;
	};
	i2s1_codec: soundcard-mach,codec {
	};
};

&i2s2_plat {
	tdm-num		= <2>;
	tx-pin		= <0 1 2 3>;
/* e.g.
 * tx-pin0-map0 = <0xFEDC3210> -> tx_pin_map[0][0] (Dout0-slot[7:0]  map channel[15:12, 3:0])
 * tx-pin0-map1 = <0x3210FEDC> -> tx_pin_map[0][1] (Dout0-slot[15:8] map channel[3:0, 15:12])
 * tx-pin1-map0 = <0x76543210> -> tx_pin_map[1][0] (Dout1-slot[7:0]  map channel[7:0])
 */
	tx-pin0-map0	= <0x76543210>;
	tx-pin0-map1	= <0xFEDCBA98>;
	tx-pin1-map0	= <0x76543210>;
	tx-pin1-map1	= <0xFEDCBA98>;
	tx-pin2-map0	= <0x76543210>;
	tx-pin2-map1	= <0xFEDCBA98>;
	tx-pin3-map0	= <0x76543210>;
	tx-pin3-map1	= <0xFEDCBA98>;
	rx-pin		= <0>;
	/* pinctrl-used; */
	/* pinctrl-names= "default","sleep"; */
	/* pinctrl-0	= <&i2s2_pins_a>; */
	/* pinctrl-1	= <&i2s2_pins_b>; */
	tx-hub-en;
	rx-sync-en;
	dai-type = "hdmi";
	status		= "okay";
};

&i2s2_mach {
	soundcard-mach,format		= "i2s";
	soundcard-mach,frame-master	= <&i2s2_cpu>;
	soundcard-mach,bitclock-master	= <&i2s2_cpu>;
	/* soundcard-mach,frame-inversion; */
	/* soundcard-mach,bitclock-inversion; */
	soundcard-mach,slot-num		= <2>;
	soundcard-mach,slot-width	= <32>;
	soundcard-mach,playback-only;
	status		= "okay";
	i2s2_cpu: soundcard-mach,cpu {
		sound-dai = <&i2s2_plat>;
		soundcard-mach,pll-fs	= <1>;
		soundcard-mach,mclk-fs	= <0>;
	};
	i2s2_codec: soundcard-mach,codec {
		sound-dai               = <&hdmi_codec>;
	};
};

&i2s3_plat {
	tdm-num		= <3>;
	tx-pin		= <0>;
	tx-pin0-map0	= <0x76543210>;
	tx-pin0-map1	= <0xFEDCBA98>;
	rx-pin		= <0>;
	/* pinctrl-used; */
	/* pinctrl-names= "default","sleep"; */
	/* pinctrl-0	= <&i2s3_pins_a>; */
	/* pinctrl-1	= <&i2s3_pins_b>; */
	tx-hub-en;
	rx-sync-en;
	status		= "disabled";
};

&i2s3_mach {
	soundcard-mach,format		= "i2s";
	soundcard-mach,frame-master	= <&i2s3_cpu>;
	soundcard-mach,bitclock-master	= <&i2s3_cpu>;
	/* soundcard-mach,frame-inversion; */
	/* soundcard-mach,bitclock-inversion; */
	soundcard-mach,slot-num		= <2>;
	soundcard-mach,slot-width	= <32>;
	status		= "disabled";
	i2s3_cpu: soundcard-mach,cpu {
		sound-dai = <&i2s3_plat>;
		soundcard-mach,pll-fs	= <1>;
		soundcard-mach,mclk-fs	= <0>;
	};
	i2s3_codec: soundcard-mach,codec {
	};
};

&vind0 {
	csi_top = <360000000>;
	csi_isp = <300000000>;
	vind_mclkpin-supply = <&reg_aldo2>;
	vind_mclkpin_vol = <1800000>;
	vind_mcsipin-supply = <&reg_cldo1>;
	vind_mcsipin_vol = <1800000>;
	vind_mipipin-supply = <&reg_cldo3>;
	vind_mipipin_vol = <3300000>;
	status = "okay";

	csi3:csi@5823000 {
		pinctrl-names = "default","sleep";
		pinctrl-0 = <&ncsi_pins_a>;
		pinctrl-1 = <&ncsi_pins_b>;
		status = "disabled";
	};

	tdm0:tdm@5908000 {
		work_mode = <0>;
	};

	isp00:isp@5900000 {
		work_mode = <0>;
	};

	isp01:isp@58ffffc {
		status = "disabled";
	};

	isp02:isp@58ffff8 {
		status = "disabled";
	};

	isp03:isp@58ffff4 {
		status = "disabled";
	};

	isp10:isp@4 {
		status = "disabled";
	};

	scaler00:scaler@5910000 {
		work_mode = <0>;
	};

	scaler01:scaler@590fffc {
		status = "disabled";
	};

	scaler02:scaler@590fff8 {
		status = "disabled";
	};

	scaler03:scaler@590fff4 {
		status = "disabled";
	};

	scaler10:scaler@5910400 {
		work_mode = <0>;
	};

	scaler11:scaler@59103fc {
		status = "disabled";
	};

	scaler12:scaler@59103f8 {
		status = "disabled";
	};

	scaler13:scaler@59103f4 {
		status = "disabled";
	};

	scaler20:scaler@5910800 {
		work_mode = <0>;
	};

	scaler21:scaler@59107fc {
		status = "disabled";
	};

	scaler22:scaler@59107f8 {
		status = "disabled";
	};

	scaler23:scaler@59107f4 {
		status = "disabled";
	};

	scaler30:scaler@5910c00 {
		work_mode = <0>;
	};

	scaler31:scaler@5910bfc {
		status = "disabled";
	};

	scaler32:scaler@5910bf8 {
		status = "disabled";
	};

	scaler33:scaler@5910bf4 {
		status = "disabled";
	};

	actuator0: actuator@2108180 {
		device_type = "actuator0";
		actuator0_name = "dw9714_act";
		actuator0_slave = <0x18>;
		actuator0_af_pwdn = <>;
		actuator0_afvdd = "afvcc-csi";
		actuator0_afvdd_vol = <3300000>;
		status = "disabled";
	};

	flash0: flash@2108190 {
		device_type = "flash0";
		flash0_type = <2>;
		flash0_en = <&r_pio PL 11 GPIO_ACTIVE_LOW>;
		flash0_mode = <>;
		flash0_flvdd = "";
		flash0_flvdd_vol = <>;
		device_id = <0>;
		status = "disabled";
	};

	sensor0:sensor@5812000 {
		device_type = "sensor0";
		sensor0_mname = "imx219";
		sensor0_twi_cci_id = <0>;
		sensor0_twi_addr = <0x20>;
		sensor0_mclk_id = <2>;
		sensor0_pos = "rear";
		sensor0_isp_used = <1>;
		sensor0_fmt = <1>;
		sensor0_stby_mode = <0>;
		sensor0_vflip = <0>;
		sensor0_hflip = <0>;
		sensor0_cameravdd-supply = <&reg_bldo3>;
		sensor0_cameravdd_vol = <2800000>;
		sensor0_iovdd-supply = <&reg_aldo2>;
		sensor0_iovdd_vol = <1800000>;
		sensor0_avdd-supply = <&reg_aldo1>;
		sensor0_avdd_vol = <2800000>;
		sensor0_dvdd-supply = <&reg_bldo4>;
		sensor0_dvdd_vol = <1500000>;
		sensor0_power_en = <>;
		//sensor0_reset = <&pio PE 9 GPIO_ACTIVE_LOW>;
		sensor0_pwdn = <&pio PH 2 GPIO_ACTIVE_HIGH>;
		status = "okay";
	};

	sensor1:sensor@5812010 {
		device_type = "sensor1";
		sensor1_mname = "ov13850_mipi";
		sensor1_twi_cci_id = <3>;
		sensor1_twi_addr = <0x20>;
		sensor1_mclk_id = <2>;
		sensor1_pos = "front";
		sensor1_isp_used = <1>;
		sensor1_fmt = <1>;
		sensor1_stby_mode = <0>;
		sensor1_vflip = <0>;
		sensor1_hflip = <0>;
		sensor1_iovdd-supply = <&reg_aldo2>;
		sensor1_iovdd_vol = <1800000>;
		sensor1_avdd-supply = <&reg_aldo1>;
		sensor1_avdd_vol = <2800000>;
		sensor1_dvdd-supply = <&reg_bldo4>;
		sensor1_dvdd_vol = <1800000>;
		sensor1_power_en = <>;
		sensor1_reset = <&pio PE 9 GPIO_ACTIVE_LOW>;
		sensor1_pwdn = <&pio PE 8 GPIO_ACTIVE_HIGH>;
		status = "okay";
	};

	vinc00:vinc@5830000 {
		vinc0_csi_sel = <2>;
		vinc0_mipi_sel = <2>;
		vinc0_isp_sel = <0>;
		vinc0_isp_tx_ch = <0>;
		vinc0_tdm_rx_sel = <0>;
		vinc0_rear_sensor_sel = <0>;
		vinc0_front_sensor_sel = <0>;
		vinc0_sensor_list = <0>;
		device_id = <0>;
		work_mode = <0x0>;
		status = "okay";
	};

	vinc01:vinc@582fffc {
		vinc1_csi_sel = <1>;
		vinc1_mipi_sel = <2>;
		vinc1_isp_sel = <1>;
		vinc1_isp_tx_ch = <0>;
		vinc1_tdm_rx_sel = <1>;
		vinc1_rear_sensor_sel = <1>;
		vinc1_front_sensor_sel = <1>;
		vinc1_sensor_list = <0>;
		device_id = <1>;
		status = "disabled";
	};

	vinc02:vinc@582fff8 {
		vinc2_csi_sel = <2>;
		vinc2_mipi_sel = <0xff>;
		vinc2_isp_sel = <2>;
		vinc2_isp_tx_ch = <2>;
		vinc2_tdm_rx_sel = <2>;
		vinc2_rear_sensor_sel = <0>;
		vinc2_front_sensor_sel = <0>;
		vinc2_sensor_list = <0>;
		device_id = <2>;
		status = "disabled";
	};

	vinc03:vinc@582fff4 {
		vinc3_csi_sel = <0>;
		vinc3_mipi_sel = <0xff>;
		vinc3_isp_sel = <0>;
		vinc3_isp_tx_ch = <0>;
		vinc3_tdm_rx_sel = <0>;
		vinc3_rear_sensor_sel = <1>;
		vinc3_front_sensor_sel = <1>;
		vinc3_sensor_list = <0>;
		device_id = <3>;
		status = "disabled";
	};

	vinc10:vinc@5831000 {
		vinc4_csi_sel = <0>;
		vinc4_mipi_sel = <0>;
		vinc4_isp_sel = <0>;
		vinc4_isp_tx_ch = <0>;
		vinc4_tdm_rx_sel = <0>;
		vinc4_rear_sensor_sel = <0>;
		vinc4_front_sensor_sel = <0>;
		vinc4_sensor_list = <0>;
		device_id = <4>;
		work_mode = <0x0>;
		status = "disabled";
	};

	vinc11:vinc@5830ffc {
		vinc5_csi_sel = <2>;
		vinc5_mipi_sel = <0xff>;
		vinc5_isp_sel = <1>;
		vinc5_isp_tx_ch = <1>;
		vinc5_tdm_rx_sel = <1>;
		vinc5_rear_sensor_sel = <0>;
		vinc5_front_sensor_sel = <0>;
		vinc5_sensor_list = <0>;
		device_id = <5>;
		status = "disabled";
	};

	vinc12:vinc@5830ff8 {
		vinc6_csi_sel = <2>;
		vinc6_mipi_sel = <0xff>;
		vinc6_isp_sel = <0>;
		vinc6_isp_tx_ch = <0>;
		vinc6_tdm_rx_sel = <0>;
		vinc6_rear_sensor_sel = <0>;
		vinc6_front_sensor_sel = <0>;
		vinc6_sensor_list = <0>;
		device_id = <6>;
		status = "disabled";
	};

	vinc13:vinc@5830ff4 {
		vinc7_csi_sel = <2>;
		vinc7_mipi_sel = <0xff>;
		vinc7_isp_sel = <0>;
		vinc7_isp_tx_ch = <0>;
		vinc7_tdm_rx_sel = <0>;
		vinc7_rear_sensor_sel = <0>;
		vinc7_front_sensor_sel = <0>;
		vinc7_sensor_list = <0>;
		device_id = <7>;
		status = "disabled";
	};

	vinc20:vinc@5832000 {
		vinc8_csi_sel = <0>;
		vinc8_mipi_sel = <0>;
		vinc8_isp_sel = <0>;
		vinc8_isp_tx_ch = <0>;
		vinc8_tdm_rx_sel = <0>;
		vinc8_rear_sensor_sel = <1>;
		vinc8_front_sensor_sel = <1>;
		vinc8_sensor_list = <0>;
		device_id = <8>;
		work_mode = <0x0>;
		status = "okay";
	};

	vinc21:vinc@5831ffc {
		vinc9_csi_sel = <2>;
		vinc9_mipi_sel = <0xff>;
		vinc9_isp_sel = <0>;
		vinc9_isp_tx_ch = <0>;
		vinc9_tdm_rx_sel = <0>;
		vinc9_rear_sensor_sel = <0>;
		vinc9_front_sensor_sel = <0>;
		vinc9_sensor_list = <0>;
		device_id = <9>;
		status = "disabled";
	};

	vinc22:vinc@5831ff8 {
		vinc10_csi_sel = <2>;
		vinc10_mipi_sel = <0xff>;
		vinc10_isp_sel = <0>;
		vinc10_isp_tx_ch = <0>;
		vinc10_tdm_rx_sel = <0>;
		vinc10_rear_sensor_sel = <0>;
		vinc10_front_sensor_sel = <0>;
		vinc10_sensor_list = <0>;
		device_id = <10>;
		status = "disabled";
	};

	vinc23:vinc@5831ff4 {
		vinc11_csi_sel = <2>;
		vinc11_mipi_sel = <0xff>;
		vinc11_isp_sel = <0>;
		vinc11_isp_tx_ch = <0>;
		vinc11_tdm_rx_sel = <0>;
		vinc11_rear_sensor_sel = <0>;
		vinc11_front_sensor_sel = <0>;
		vinc11_sensor_list = <0>;
		device_id = <11>;
		status = "disabled";
	};

	vinc30:vinc@5833000 {
		vinc12_csi_sel = <2>;
		vinc12_mipi_sel = <2>;
		vinc12_isp_sel = <0>;
		vinc12_isp_tx_ch = <0>;
		vinc12_tdm_rx_sel = <0>;
		vinc12_rear_sensor_sel = <1>;
		vinc12_front_sensor_sel = <1>;
		vinc12_sensor_list = <0>;
		device_id = <12>;
		work_mode = <0x0>;
		status = "disabled";
	};

	vinc31:vinc@5832ffc {
		vinc13_csi_sel = <2>;
		vinc13_mipi_sel = <0xff>;
		vinc13_isp_sel = <0>;
		vinc13_isp_tx_ch = <0>;
		vinc13_tdm_rx_sel = <0>;
		vinc13_rear_sensor_sel = <0>;
		vinc13_front_sensor_sel = <0>;
		vinc13_sensor_list = <0>;
		device_id = <13>;
		status = "disabled";
	};

	vinc32:vinc@5832ff8 {
		vinc14_csi_sel = <2>;
		vinc14_mipi_sel = <0xff>;
		vinc14_isp_sel = <0>;
		vinc14_isp_tx_ch = <0>;
		vinc14_tdm_rx_sel = <0>;
		vinc14_rear_sensor_sel = <0>;
		vinc14_front_sensor_sel = <0>;
		vinc14_sensor_list = <0>;
		device_id = <14>;
		status = "disabled";
	};

	vinc33:vinc@5832ff4 {
		vinc15_csi_sel = <2>;
		vinc15_mipi_sel = <0xff>;
		vinc15_isp_sel = <0>;
		vinc15_isp_tx_ch = <0>;
		vinc15_tdm_rx_sel = <0>;
		vinc15_rear_sensor_sel = <0>;
		vinc15_front_sensor_sel = <0>;
		vinc15_sensor_list = <0>;
		device_id = <15>;
		status = "disabled";
	};

	vinc40:vinc@5834000 {
		vinc16_csi_sel = <2>;
		vinc16_mipi_sel = <0xff>;
		vinc16_isp_sel = <0>;
		vinc16_isp_tx_ch = <0>;
		vinc16_tdm_rx_sel = <0>;
		vinc16_rear_sensor_sel = <0>;
		vinc16_front_sensor_sel = <0>;
		vinc16_sensor_list = <0>;
		device_id = <16>;
		status = "disabled";
	};

	vinc50:vinc@5835000 {
		vinc17_csi_sel = <2>;
		vinc17_mipi_sel = <0xff>;
		vinc17_isp_sel = <0>;
		vinc17_isp_tx_ch = <0>;
		vinc17_tdm_rx_sel = <0>;
		vinc17_rear_sensor_sel = <0>;
		vinc17_front_sensor_sel = <0>;
		vinc17_sensor_list = <0>;
		device_id = <17>;
		status = "disabled";
	};
};

&gmac1 {
	phy-mode = "rgmii";
	pinctrl-names = "default", "sleep";
	pinctrl-0 = <&gmac1_pins_default>;
	pinctrl-1 = <&gmac1_pins_sleep>;
	aw,soc-phy25m;
	tx-delay = <1>;
	rx-delay = <3>;
	dwmac3v3-supply = <&reg_cldo3>;
	status = "okay";
};

&gmac1_phy0 {
	reset-gpios = <&pio PI 15 GPIO_ACTIVE_LOW>;
};

&spi0 {
	clock-frequency = <100000000>;
	pinctrl-names = "default","sleep";
	pinctrl-0 = <&spi0_pin_default>;
	pinctrl-1 = <&spi0_pin_sleep>;

	sunxi,spi-num-cs = <1>;
	sunxi,spi-bus-mode = <SUNXI_SPI_BUS_MASTER>;
	sunxi,spi-cs-mode = <SUNXI_SPI_CS_AUTO>;
	status = "okay";

        spi_board0 {
                device_type = "spi_board0";
                compatible = "spi-nor";
                spi-max-frequency = <500000>;
                m25p,fast-read = <1>;
                /*individual_lock;*/
                reg = <0x0>;
                spi-rx-bus-width=<0x01>;
                spi-tx-bus-width=<0x01>;
                status="disabled";
        };

	spidev@0 {
		reg = <0>;
		compatible = "rohm,dh2228fv";
		spi-max-frequency = <500000>;
		spi-rx-bus-width = <0x1>;
		spi-tx-bus-width = <0x1>;
	};
};

&spi1 {
	clock-frequency = <100000000>;
	pinctrl-names = "default","sleep";
	pinctrl-0 = <&spi1_pin_default>;
	pinctrl-1 = <&spi1_pin_sleep>;

	sunxi,spi-num-cs = <1>;
	sunxi,spi-bus-mode = <SUNXI_SPI_BUS_MASTER>;
	sunxi,spi-cs-mode = <SUNXI_SPI_CS_AUTO>;
	status = "disabled";

	spidev@0 {
		reg = <0>;
		compatible = "rohm,dh2228fv";
		spi-max-frequency = <500000>;
		spi-rx-bus-width = <0x1>;
		spi-tx-bus-width = <0x1>;
	};
};

&spi2 {
	clock-frequency = <100000000>;
	pinctrl-names = "default","sleep";
	pinctrl-0 = <&spi2_pin_default>;
	pinctrl-1 = <&spi2_pin_sleep>;

	sunxi,spi-num-cs = <1>;
	sunxi,spi-bus-mode = <SUNXI_SPI_BUS_MASTER>;
	sunxi,spi-cs-mode = <SUNXI_SPI_CS_AUTO>;
	status = "disabled";

	spidev@0 {
		reg = <0>;
		compatible = "rohm,dh2228fv";
		spi-max-frequency = <500000>;
		spi-rx-bus-width = <0x1>;
		spi-tx-bus-width = <0x1>;
	};
};

&dram {
	dram_para00 = <0x000004b0>;
	dram_para01 = <0x00000008>;
	dram_para02 = <0x07070707>;
	dram_para03 = <0x0d0d0d0d>;
	dram_para04 = <0x00000e0e>;
	dram_para05 = <0x84848484>;
	dram_para06 = <0x0000310a>;
	dram_para07 = <0x10001000>;
	dram_para08 = <0x00000000>;
	dram_para09 = <0x00000054>;
	dram_para10 = <0x0000002d>;
	dram_para11 = <0x00000033>;
	dram_para12 = <0x00000003>;
	dram_para13 = <0x00000000>;
	dram_para14 = <0x00000000>;
	dram_para15 = <0x00000004>;
	dram_para16 = <0x00000072>;
	dram_para17 = <0x00000000>;
	dram_para18 = <0x0000000c>;
	dram_para19 = <0x00000000>;
	dram_para20 = <0x00000000>;
	dram_para21 = <0x00000026>;
	dram_para22 = <0x80808080>;
	dram_para23 = <0x06060606>;
	dram_para24 = <0x5f090503>;
	dram_para25 = <0x00000000>;
	dram_para26 = <0x38000000>;
	dram_para27 = <0x802f3333>;
	dram_para28 = <0xc6c4c2c0>;
	dram_para29 = <0x3a373233>;
	dram_para30 = <0x00006065>;
	dram_para31 = <0x48484848>;
	dram_para32 = <0x00000000>;
	dram_para33 = <0x00000000>;
	dram_para34 = <0x00000000>;
	dram_para35 = <0x00000000>;
	dram_para36 = <0x00000000>;
	dram_para37 = <0x00000000>;
	dram_para38 = <0x00000000>;
	dram_para39 = <0x00000000>;
	dram_para40 = <0x00000000>;
	dram_para41 = <0x00000000>;
	dram_para42 = <0x00000000>;
	dram_para43 = <0x00000000>;
	dram_para44 = <0x00000000>;
	dram_para45 = <0x00000000>;
	dram_para46 = <0x00000000>;
	dram_para47 = <0x00000000>;
	dram_para48 = <0x28282828>;
	dram_para49 = <0x00000000>;
	dram_para50 = <0x00000000>;
	dram_para51 = <0x00000000>;
	dram_para52 = <0x00000000>;
	dram_para53 = <0x00000000>;
	dram_para54 = <0x00000000>;
	dram_para55 = <0x00000000>;
	dram_para56 = <0xb2b4b0b2>;
	dram_para57 = <0x00000000>;
	dram_para58 = <0x00000000>;
	dram_para59 = <0x00000000>;
	dram_para60 = <0x00000000>;
	dram_para61 = <0x00000000>;
	dram_para62 = <0x00000000>;
	dram_para63 = <0x00000000>;
	dram_para64 = <0x0c0c0c0c>;
	dram_para65 = <0x00000000>;
	dram_para66 = <0x00000000>;
	dram_para67 = <0x00000000>;
	dram_para68 = <0x00000000>;
	dram_para69 = <0x00000000>;
	dram_para70 = <0x00000000>;
	dram_para71 = <0x00000000>;
	dram_para72 = <0x9ea09ea0>;
	dram_para73 = <0x00000000>;
	dram_para74 = <0x00000000>;
	dram_para75 = <0x00000000>;
	dram_para76 = <0x00000000>;
	dram_para77 = <0x00000000>;
	dram_para78 = <0x00000000>;
	dram_para79 = <0x00000000>;
	dram_para80 = <0x0c0c0c0c>;
	dram_para81 = <0x00000000>;
	dram_para82 = <0x00000000>;
	dram_para83 = <0x00000000>;
	dram_para84 = <0x00000000>;
	dram_para85 = <0x00000000>;
	dram_para86 = <0x00000000>;
	dram_para87 = <0x00000000>;
	dram_para88 = <0x96969696>;
	dram_para89 = <0x00000000>;
	dram_para90 = <0x00000000>;
	dram_para91 = <0x00000000>;
	dram_para92 = <0x00000000>;
	dram_para93 = <0x00000000>;
	dram_para94 = <0x00000000>;
	dram_para95 = <0x00000000>;
	compatible = "allwinner,dram";
	clocks = <0x0000001a 0x00000000>;
	clock-names = "pll_ddr";
	phandle = <0x00000143>;
};

&cpul_thermal_zone {
	cpul_trips: trips {
		cpul_crit: cpu_crit@0 {
			temperature = <115000>;
			type = "critical";
			hysteresis = <0>;
		};
	};
};

&cpub_thermal_zone {
	cpub_trips: trips {
		cpub_crit: cpu_crit@0 {
			temperature = <115000>;
			type = "critical";
			hysteresis = <0>;
		};
	};
};

&gpu_thermal_zone {
	gpu_trips: trips {
		gpu_crit: gpu_crit@0 {
			temperature = <115000>;
			type = "critical";
			hysteresis = <0>;
		};
	};
};

